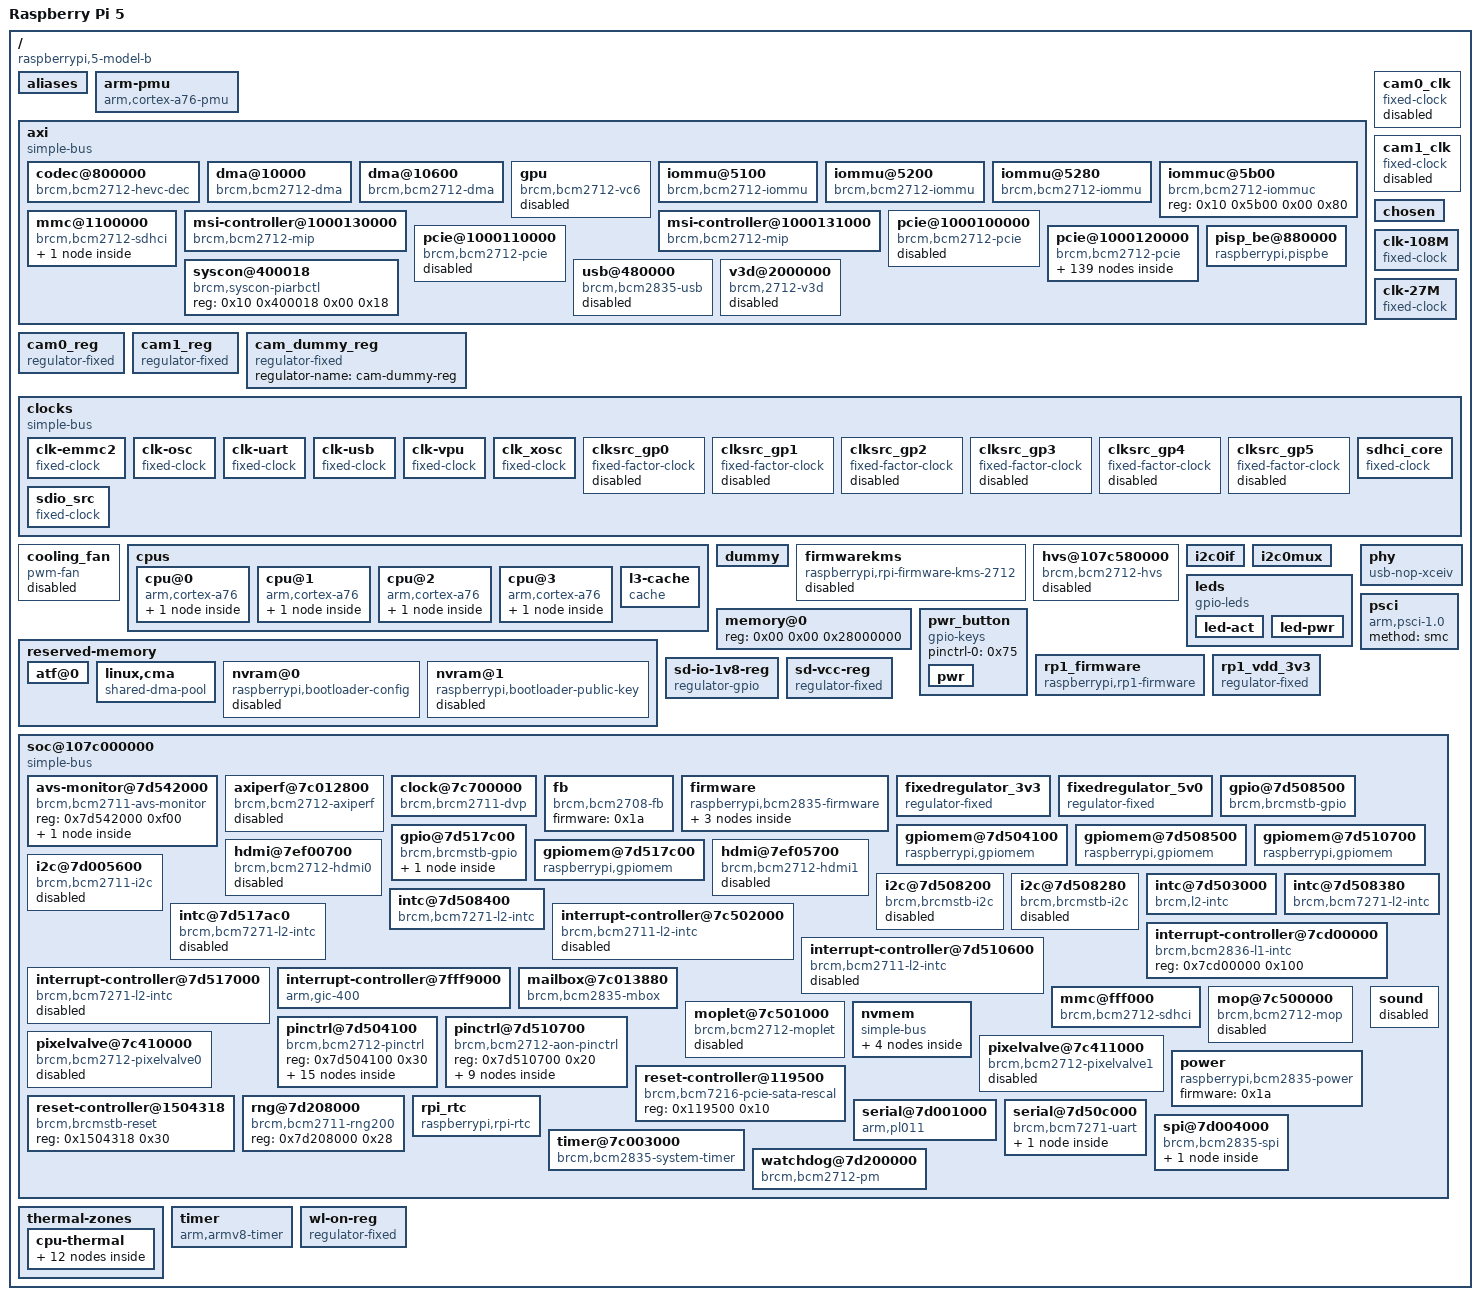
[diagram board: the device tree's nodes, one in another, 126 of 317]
/dts-v1/;

/ {
	#address-cells = <0x02>;
	#size-cells = <0x01>;
	compatible = "raspberrypi,5-model-b", "brcm,bcm2712";
	interrupt-parent = <0x01>;
	model = "Raspberry Pi 5";

	__overrides__ {
		act_led_activelow = "", "", "", "]gpios:8";
		act_led_gpio = [00 00 00 5d 67 70 69 6f 73 3a 34 00 00 00 00 5d 67 70 69 6f 73 3a 30 3d 00 00 00 00 2e];
		act_led_trigger = "", "", "", "]linux,default-trigger";
		axiperf = "", "", "", "^status";
		bdaddr = "", "", "", "_local-bd-address[";
		button_debounce = "", "", "", "`debounce-interval:0";
		cam0_reg = "", "", "", "rstatus";
		cam0_reg_gpio = [00 00 00 72 67 70 69 6f 3a 34 00 00 00 00 72 67 70 69 6f 3a 30 3d 00 00 00 00 2e];
		cam1_reg = "", "", "", "sstatus";
		cam1_reg_gpio = [00 00 00 73 67 70 69 6f 3a 34 00 00 00 00 73 67 70 69 6f 3a 30 3d 00 00 00 00 2e];
		cooling_fan = "", "", "", "Tstatus", "", "", "", "astatus";
		drm_fb0_rp1_dpi = "", "", "", "bdrm-fb0=", "/axi/pcie@1000120000/rp1/dpi@148000";
		drm_fb0_rp1_dsi0 = "", "", "", "bdrm-fb0=", "/axi/pcie@1000120000/rp1/dsi@110000";
		drm_fb0_rp1_dsi1 = "", "", "", "bdrm-fb0=", "/axi/pcie@1000120000/rp1/dsi@128000";
		drm_fb0_vc4 = "", "", "", "bdrm-fb0=", "/axi/gpu";
		drm_fb1_rp1_dpi = "", "", "", "bdrm-fb1=", "/axi/pcie@1000120000/rp1/dpi@148000";
		drm_fb1_rp1_dsi0 = "", "", "", "bdrm-fb1=", "/axi/pcie@1000120000/rp1/dsi@110000";
		drm_fb1_rp1_dsi1 = "", "", "", "bdrm-fb1=", "/axi/pcie@1000120000/rp1/dsi@128000";
		drm_fb1_vc4 = "", "", "", "bdrm-fb1=", "/axi/gpu";
		drm_fb2_rp1_dpi = "", "", "", "bdrm-fb2=", "/axi/pcie@1000120000/rp1/dpi@148000";
		drm_fb2_rp1_dsi0 = "", "", "", "bdrm-fb2=", "/axi/pcie@1000120000/rp1/dsi@110000";
		drm_fb2_rp1_dsi1 = "", "", "", "bdrm-fb2=", "/axi/pcie@1000120000/rp1/dsi@128000";
		drm_fb2_vc4 = "", "", "", "bdrm-fb2=", "/axi/gpu";
		eth_led0 = "", "", "", "?led-modes:0";
		eth_led1 = "", "", "", "?led-modes:4";
		eth_max_speed = "", "", "", "?max-speed:0";
		fan_temp0 = "", "", "", "Stemperature:0";
		fan_temp0_hyst = "", "", "", "Shysteresis:0";
		fan_temp0_speed = "", "", "", "Tcooling-levels:4";
		fan_temp1 = "", "", "", "Utemperature:0";
		fan_temp1_hyst = "", "", "", "Uhysteresis:0";
		fan_temp1_speed = "", "", "", "Tcooling-levels:8";
		fan_temp2 = "", "", "", "Vtemperature:0";
		fan_temp2_hyst = "", "", "", "Vhysteresis:0";
		fan_temp2_speed = "", "", "", "Tcooling-levels:12";
		fan_temp3 = "", "", "", "Wtemperature:0";
		fan_temp3_hyst = "", "", "", "Whysteresis:0";
		fan_temp3_speed = "", "", "", "Tcooling-levels:16";
		i2c = "", "", "", "cstatus";
		i2c0 = "", "", "", "fstatus";
		i2c0_baudrate = "", "", "", "fclock-frequency:0";
		i2c1 = "", "", "", "cstatus";
		i2c1_baudrate = "", "", "", "cclock-frequency:0";
		i2c_arm = "", "", "", "cstatus";
		i2c_arm_baudrate = "", "", "", "cclock-frequency:0";
		i2c_baudrate = "", "", "", "cclock-frequency:0";
		i2c_csi_dsi = "", "", "", "dstatus";
		i2c_csi_dsi0 = "", "", "", "estatus";
		i2c_csi_dsi1 = "", "", "", "dstatus";
		i2c_vc = "", "", "", "fstatus";
		i2c_vc_baudrate = "", "", "", "fclock-frequency:0";
		krnbt = "", "", "", "_status";
		nvme = "", "", "", "gstatus";
		nvmem_cust_rw = "", "", "", "hrw?";
		nvmem_mac_rw = "", "", "", "irw?";
		nvmem_priv_rw = "", "", "", "jrw?";
		pcie_tperst_clk_ms = "", "", "", "gbrcm,tperst-clk-ms:0";
		pciex1 = "", "", "", "gstatus";
		pciex1_gen = "", "", "", "gmax-link-speed:0";
		pciex1_no_l0s = "", "", "", "gaspm-no-l0s?";
		pciex1_tperst_clk_ms = "", "", "", "gbrcm,tperst-clk-ms:0";
		pwr_led_activelow = "", "", "", "kgpios:8";
		pwr_led_gpio = "", "", "", "kgpios:4";
		pwr_led_trigger = "", "", "", "klinux,default-trigger";
		random = "", "", "", "lstatus";
		rtc = "", "", "", "mstatus";
		rtc_bbat_vchg = "", "", "", "mtrickle-charge-microvolt:0";
		sd_cqe = "", "", "", "tsupports-cqe:0";
		spi = "", "", "", "nstatus";
		strict_gpiod = "", "", "", "obootargs=pinctrl_rp1.persist_gpio_outputs=n";
		suspend = "", "", "", "`linux,code:0=205";
		uart0 = "", "", "", "pstatus";
		uart0_console = "", "", "", "pstatus", "", "", "", "bconsole=", "/axi/pcie@1000120000/rp1/serial@30000";
		uart0_dma = [00 00 00 70 64 6d 61 73 3a 30 3d 00 00 00 00 2b 00 00 00 70 64 6d 61 73 3a 34 3d 00 00 00 00 1a 00 00 00 70 64 6d 61 73 3a 38 3d 00 00 00 00 2b 00 00 00 70 64 6d 61 73 3a 31 32 3d 00 00 00 00 19 00 00 00 70 64 6d 61 2d 6e 61 6d 65 73 5b 3d 37 34 37 38 30 30 37 32 37 38 30 30 00];
		watchdog = "", "", "", "Learly-watchdog?";
		wifiaddr = "", "", "", "qlocal-mac-address[";
	};

	__symbols__ {
		aliases = "/aliases";
		aon_intr = "/soc@107c000000/interrupt-controller@7d510600";
		aon_pwm_1pin = "/soc@107c000000/pinctrl@7d510700/aon_pwm_1pin";
		aux = "/dummy";
		avs_monitor = "/soc@107c000000/avs-monitor@7d542000";
		axi = "/axi";
		axiperf = "/soc@107c000000/axiperf@7c012800";
		bcm_reset = "/soc@107c000000/reset-controller@1504318";
		blconfig = "/reserved-memory/nvram@0";
		blpubkey = "/reserved-memory/nvram@1";
		bluetooth = "/soc@107c000000/serial@7d50c000/bluetooth";
		bsc_irq = "/soc@107c000000/intc@7d508380";
		bsc_m1_agpio13_pins = "/soc@107c000000/pinctrl@7d510700/bsc_m1_agpio13_pins";
		bsc_m2_sgpio4_pins = "/soc@107c000000/pinctrl@7d510700/bsc_m2_sgpio4_pins";
		bsc_pmu_sgpio4_pins = "/soc@107c000000/pinctrl@7d510700/bsc_pmu_sgpio4_pins";
		bt_shutdown_pins = "/soc@107c000000/pinctrl@7d504100/bt_shutdown_pins";
		cam0_clk = "/cam0_clk";
		cam0_reg = "/cam0_reg";
		cam1_clk = "/cam1_clk";
		cam1_reg = "/cam1_reg";
		cam_dummy_reg = "/cam_dummy_reg";
		chosen = "/chosen";
		clk_108MHz = "/clk-108M";
		clk_27MHz = "/clk-27M";
		clk_emmc2 = "/clocks/clk-emmc2";
		clk_osc = "/clocks/clk-osc";
		clk_uart = "/clocks/clk-uart";
		clk_usb = "/clocks/clk-usb";
		clk_vpu = "/clocks/clk-vpu";
		clk_xosc = "/clocks/clk_xosc";
		clksrc_gp0 = "/clocks/clksrc_gp0";
		clksrc_gp1 = "/clocks/clksrc_gp1";
		clksrc_gp2 = "/clocks/clksrc_gp2";
		clksrc_gp3 = "/clocks/clksrc_gp3";
		clksrc_gp4 = "/clocks/clksrc_gp4";
		clksrc_gp5 = "/clocks/clksrc_gp5";
		clocks = "/clocks";
		cma = "/reserved-memory/linux,cma";
		cooling_maps = "/thermal-zones/cpu-thermal/cooling-maps";
		cpu0 = "/cpus/cpu@0";
		cpu1 = "/cpus/cpu@1";
		cpu2 = "/cpus/cpu@2";
		cpu3 = "/cpus/cpu@3";
		cpu_crit = "/thermal-zones/cpu-thermal/trips/cpu-crit";
		cpu_hot = "/thermal-zones/cpu-thermal/trips/cpu-hot";
		cpu_l2_irq = "/soc@107c000000/intc@7d503000";
		cpu_tepid = "/thermal-zones/cpu-thermal/trips/cpu-tepid";
		cpu_thermal = "/thermal-zones/cpu-thermal";
		cpu_vhot = "/thermal-zones/cpu-thermal/trips/cpu-vhot";
		cpu_warm = "/thermal-zones/cpu-thermal/trips/cpu-warm";
		cpus = "/cpus";
		csi0 = "/axi/pcie@1000120000/rp1/csi@110000";
		csi1 = "/axi/pcie@1000120000/rp1/csi@128000";
		ddc0 = "/soc@107c000000/i2c@7d508200";
		ddc1 = "/soc@107c000000/i2c@7d508280";
		disp_intr = "/soc@107c000000/interrupt-controller@7c502000";
		dma32 = "/axi/dma@10000";
		dma40 = "/axi/dma@10600";
		dpi = "/axi/pcie@1000120000/rp1/dpi@148000";
		dpi_16bit_cpadhi_gpio0 = "/axi/pcie@1000120000/rp1/gpio@d0000/rp1_dpi_16bit_cpadhi_gpio0";
		dpi_16bit_cpadhi_gpio2 = "/axi/pcie@1000120000/rp1/gpio@d0000/rp1_dpi_16bit_cpadhi_gpio2";
		dpi_16bit_gpio0 = "/axi/pcie@1000120000/rp1/gpio@d0000/rp1_dpi_16bit_gpio0";
		dpi_16bit_gpio2 = "/axi/pcie@1000120000/rp1/gpio@d0000/rp1_dpi_16bit_gpio2";
		dpi_18bit_cpadhi_gpio0 = "/axi/pcie@1000120000/rp1/gpio@d0000/rp1_dpi_18bit_cpadhi_gpio0";
		dpi_18bit_cpadhi_gpio2 = "/axi/pcie@1000120000/rp1/gpio@d0000/rp1_dpi_18bit_cpadhi_gpio2";
		dpi_18bit_gpio0 = "/axi/pcie@1000120000/rp1/gpio@d0000/rp1_dpi_18bit_gpio0";
		dpi_18bit_gpio2 = "/axi/pcie@1000120000/rp1/gpio@d0000/rp1_dpi_18bit_gpio2";
		dpi_gpio0 = "/axi/pcie@1000120000/rp1/gpio@d0000/rp1_dpi_24bit_gpio0";
		dpi_gpio1 = "/axi/pcie@1000120000/rp1/gpio@d0000/rp1_dpi_24bit_gpio2";
		dsi0 = "/axi/pcie@1000120000/rp1/dsi@110000";
		dsi1 = "/axi/pcie@1000120000/rp1/dsi@128000";
		dummy = "/dummy";
		dvp = "/soc@107c000000/clock@7c700000";
		emmc_aon_cd_pins = "/soc@107c000000/pinctrl@7d510700/emmc_aon_cd_pins";
		emmc_sd_pulls = "/soc@107c000000/pinctrl@7d504100/emmc_sd_pulls";
		fan = "/cooling_fan";
		fb = "/soc@107c000000/fb";
		firmware = "/soc@107c000000/firmware";
		firmware_clocks = "/soc@107c000000/firmware/clocks";
		firmwarekms = "/firmwarekms";
		gicv2 = "/soc@107c000000/interrupt-controller@7fff9000";
		gio = "/soc@107c000000/gpio@7d508500";
		gio_aon = "/soc@107c000000/gpio@7d517c00";
		gpio = "/axi/pcie@1000120000/rp1/gpio@d0000";
		hdmi0 = "/soc@107c000000/hdmi@7ef00700";
		hdmi1 = "/soc@107c000000/hdmi@7ef05700";
		hevc_dec = "/axi/codec@800000";
		hvs = "/hvs@107c580000";
		i2c0 = "/axi/pcie@1000120000/rp1/i2c@70000";
		i2c0_pins = "/axi/pcie@1000120000/rp1/gpio@d0000/rp1_i2c0_0_1";
		i2c0if = "/i2c0if";
		i2c0mux = "/i2c0mux";
		i2c1 = "/axi/pcie@1000120000/rp1/i2c@74000";
		i2c10 = "/soc@107c000000/i2c@7d005600";
		i2c1_pins = "/axi/pcie@1000120000/rp1/gpio@d0000/rp1_i2c1_2_3";
		i2c2 = "/axi/pcie@1000120000/rp1/i2c@78000";
		i2c2_pins = "/axi/pcie@1000120000/rp1/gpio@d0000/rp1_i2c2_4_5";
		i2c3 = "/axi/pcie@1000120000/rp1/i2c@7c000";
		i2c3_m4_agpio0_pins = "/soc@107c000000/pinctrl@7d510700/i2c3_m4_agpio0_pins";
		i2c3_pins = "/axi/pcie@1000120000/rp1/gpio@d0000/rp1_i2c3_6_7";
		i2c4 = "/axi/pcie@1000120000/rp1/i2c@80000";
		i2c5 = "/axi/pcie@1000120000/rp1/i2c@84000";
		i2c6 = "/axi/pcie@1000120000/rp1/i2c@88000";
		i2c_arm = "/axi/pcie@1000120000/rp1/i2c@74000";
		i2c_csi_dsi = "/axi/pcie@1000120000/rp1/i2c@80000";
		i2c_csi_dsi0 = "/axi/pcie@1000120000/rp1/i2c@88000";
		i2c_csi_dsi1 = "/axi/pcie@1000120000/rp1/i2c@80000";
		i2c_vc = "/axi/pcie@1000120000/rp1/i2c@70000";
		i2s = "/axi/pcie@1000120000/rp1/i2s@a0000";
		i2s_clk_consumer = "/axi/pcie@1000120000/rp1/i2s@a4000";
		i2s_clk_producer = "/axi/pcie@1000120000/rp1/i2s@a0000";
		iommu2 = "/axi/iommu@5100";
		iommu4 = "/axi/iommu@5200";
		iommu5 = "/axi/iommu@5280";
		iommuc = "/axi/iommuc@5b00";
		l2_cache_l0 = "/cpus/cpu@0/l2-cache-l0";
		l2_cache_l1 = "/cpus/cpu@1/l2-cache-l1";
		l2_cache_l2 = "/cpus/cpu@2/l2-cache-l2";
		l2_cache_l3 = "/cpus/cpu@3/l2-cache-l3";
		l3_cache = "/cpus/l3-cache";
		led_act = "/leds/led-act";
		led_pwr = "/leds/led-pwr";
		leds = "/leds";
		local_intc = "/soc@107c000000/interrupt-controller@7cd00000";
		mailbox = "/soc@107c000000/mailbox@7c013880";
		main_aon_irq = "/soc@107c000000/intc@7d517ac0";
		main_irq = "/soc@107c000000/intc@7d508400";
		mip0 = "/axi/msi-controller@1000130000";
		mip1 = "/axi/msi-controller@1000131000";
		mop = "/soc@107c000000/mop@7c500000";
		moplet = "/soc@107c000000/moplet@7c501000";
		nvmem_cust = "/soc@107c000000/nvmem/nvmem_cust";
		nvmem_mac = "/soc@107c000000/nvmem/nvmem_mac";
		nvmem_otp = "/soc@107c000000/nvmem/nvmem_otp";
		nvmem_priv = "/soc@107c000000/nvmem/nvmem_priv";
		pcie0 = "/axi/pcie@1000100000";
		pcie1 = "/axi/pcie@1000110000";
		pcie2 = "/axi/pcie@1000120000";
		pcie_rescal = "/soc@107c000000/reset-controller@119500";
		pciex1 = "/axi/pcie@1000110000";
		pciex4 = "/axi/pcie@1000120000";
		phy1 = "/axi/pcie@1000120000/rp1/ethernet@100000/ethernet-phy@1";
		pinctrl = "/soc@107c000000/pinctrl@7d504100";
		pinctrl_aon = "/soc@107c000000/pinctrl@7d510700";
		pio = "/axi/pcie@1000120000/rp1/pio@178000";
		pisp_be = "/axi/pisp_be@880000";
		pixelvalve0 = "/soc@107c000000/pixelvalve@7c410000";
		pixelvalve1 = "/soc@107c000000/pixelvalve@7c411000";
		pm = "/soc@107c000000/watchdog@7d200000";
		power = "/soc@107c000000/power";
		pwm = "/axi/pcie@1000120000/rp1/pwm@98000";
		pwm0 = "/axi/pcie@1000120000/rp1/pwm@98000";
		pwm1 = "/axi/pcie@1000120000/rp1/pwm@9c000";
		pwm_aon_agpio1_pins = "/soc@107c000000/pinctrl@7d510700/pwm_aon_agpio1_pins";
		pwm_aon_agpio4_pins = "/soc@107c000000/pinctrl@7d510700/pwm_aon_agpio4_pins";
		pwm_aon_agpio7_pins = "/soc@107c000000/pinctrl@7d510700/pwm_aon_agpio7_pins";
		pwr_button_pins = "/soc@107c000000/pinctrl@7d504100/pwr_button_pins";
		pwr_key = "/pwr_button/pwr";
		random = "/soc@107c000000/rng@7d208000";
		reset = "/soc@107c000000/firmware/reset";
		rmem = "/reserved-memory";
		rp1 = "/axi/pcie@1000120000/rp1";
		rp1_adc = "/axi/pcie@1000120000/rp1/adc@c8000";
		rp1_audio_out = "/axi/pcie@1000120000/rp1/audio_out@94000";
		rp1_audio_out_12_13 = "/axi/pcie@1000120000/rp1/gpio@d0000/rp1_audio_out_12_13";
		rp1_clocks = "/axi/pcie@1000120000/rp1/clocks@18000";
		rp1_csi0 = "/axi/pcie@1000120000/rp1/csi@110000";
		rp1_csi1 = "/axi/pcie@1000120000/rp1/csi@128000";
		rp1_dma = "/axi/pcie@1000120000/rp1/dma@188000";
		rp1_dpi = "/axi/pcie@1000120000/rp1/dpi@148000";
		rp1_dpi_16bit_cpadhi_gpio0 = "/axi/pcie@1000120000/rp1/gpio@d0000/rp1_dpi_16bit_cpadhi_gpio0";
		rp1_dpi_16bit_cpadhi_gpio2 = "/axi/pcie@1000120000/rp1/gpio@d0000/rp1_dpi_16bit_cpadhi_gpio2";
		rp1_dpi_16bit_gpio0 = "/axi/pcie@1000120000/rp1/gpio@d0000/rp1_dpi_16bit_gpio0";
		rp1_dpi_16bit_gpio2 = "/axi/pcie@1000120000/rp1/gpio@d0000/rp1_dpi_16bit_gpio2";
		rp1_dpi_16bit_pad666_gpio0 = "/axi/pcie@1000120000/rp1/gpio@d0000/rp1_dpi_16bit_pad666_gpio0";
		rp1_dpi_16bit_pad666_gpio2 = "/axi/pcie@1000120000/rp1/gpio@d0000/rp1_dpi_16bit_pad666_gpio2";
		rp1_dpi_18bit_cpadhi_gpio0 = "/axi/pcie@1000120000/rp1/gpio@d0000/rp1_dpi_18bit_cpadhi_gpio0";
		rp1_dpi_18bit_cpadhi_gpio2 = "/axi/pcie@1000120000/rp1/gpio@d0000/rp1_dpi_18bit_cpadhi_gpio2";
		rp1_dpi_18bit_gpio0 = "/axi/pcie@1000120000/rp1/gpio@d0000/rp1_dpi_18bit_gpio0";
		rp1_dpi_18bit_gpio2 = "/axi/pcie@1000120000/rp1/gpio@d0000/rp1_dpi_18bit_gpio2";
		rp1_dpi_24bit_gpio0 = "/axi/pcie@1000120000/rp1/gpio@d0000/rp1_dpi_24bit_gpio0";
		rp1_dpi_24bit_gpio2 = "/axi/pcie@1000120000/rp1/gpio@d0000/rp1_dpi_24bit_gpio2";
		rp1_dpi_hvsync = "/axi/pcie@1000120000/rp1/gpio@d0000/rp1_dpi_hvsync";
		rp1_dsi0 = "/axi/pcie@1000120000/rp1/dsi@110000";
		rp1_dsi1 = "/axi/pcie@1000120000/rp1/dsi@128000";
		rp1_eth = "/axi/pcie@1000120000/rp1/ethernet@100000";
		rp1_firmware = "/rp1_firmware";
		rp1_fw_shmem = "/axi/pcie@1000120000/rp1/sram@400000/shmem@ff00";
		rp1_gpclksrc0_gpio20 = "/axi/pcie@1000120000/rp1/gpio@d0000/rp1_gpclksrc0_gpio20";
		rp1_gpclksrc0_gpio4 = "/axi/pcie@1000120000/rp1/gpio@d0000/rp1_gpclksrc0_gpio4";
		rp1_gpclksrc1_gpio18 = "/axi/pcie@1000120000/rp1/gpio@d0000/rp1_gpclksrc1_gpio18";
		rp1_gpclksrc1_gpio21 = "/axi/pcie@1000120000/rp1/gpio@d0000/rp1_gpclksrc1_gpio21";
		rp1_gpclksrc1_gpio5 = "/axi/pcie@1000120000/rp1/gpio@d0000/rp1_gpclksrc1_gpio5";
		rp1_gpio = "/axi/pcie@1000120000/rp1/gpio@d0000";
		rp1_i2c0 = "/axi/pcie@1000120000/rp1/i2c@70000";
		rp1_i2c0_0_1 = "/axi/pcie@1000120000/rp1/gpio@d0000/rp1_i2c0_0_1";
		rp1_i2c0_8_9 = "/axi/pcie@1000120000/rp1/gpio@d0000/rp1_i2c0_8_9";
		rp1_i2c1 = "/axi/pcie@1000120000/rp1/i2c@74000";
		rp1_i2c1_10_11 = "/axi/pcie@1000120000/rp1/gpio@d0000/rp1_i2c1_10_11";
		rp1_i2c1_2_3 = "/axi/pcie@1000120000/rp1/gpio@d0000/rp1_i2c1_2_3";
		rp1_i2c2 = "/axi/pcie@1000120000/rp1/i2c@78000";
		rp1_i2c2_12_13 = "/axi/pcie@1000120000/rp1/gpio@d0000/rp1_i2c2_12_13";
		rp1_i2c2_4_5 = "/axi/pcie@1000120000/rp1/gpio@d0000/rp1_i2c2_4_5";
		rp1_i2c3 = "/axi/pcie@1000120000/rp1/i2c@7c000";
		rp1_i2c3_14_15 = "/axi/pcie@1000120000/rp1/gpio@d0000/rp1_i2c3_14_15";
		rp1_i2c3_22_23 = "/axi/pcie@1000120000/rp1/gpio@d0000/rp1_i2c3_22_23";
		rp1_i2c3_6_7 = "/axi/pcie@1000120000/rp1/gpio@d0000/rp1_i2c3_6_7";
		rp1_i2c4 = "/axi/pcie@1000120000/rp1/i2c@80000";
		rp1_i2c4_34_35 = "/axi/pcie@1000120000/rp1/gpio@d0000/rp1_i2c4_34_35";
		rp1_i2c4_40_41 = "/axi/pcie@1000120000/rp1/gpio@d0000/rp1_i2c4_40_41";
		rp1_i2c5 = "/axi/pcie@1000120000/rp1/i2c@84000";
		rp1_i2c5_44_45 = "/axi/pcie@1000120000/rp1/gpio@d0000/rp1_i2c5_44_45";
		rp1_i2c6 = "/axi/pcie@1000120000/rp1/i2c@88000";
		rp1_i2c6_38_39 = "/axi/pcie@1000120000/rp1/gpio@d0000/rp1_i2c6_38_39";
		rp1_i2s0 = "/axi/pcie@1000120000/rp1/i2s@a0000";
		rp1_i2s0_18_21 = "/axi/pcie@1000120000/rp1/gpio@d0000/rp1_i2s0_18_21";
		rp1_i2s1 = "/axi/pcie@1000120000/rp1/i2s@a4000";
		rp1_i2s1_18_21 = "/axi/pcie@1000120000/rp1/gpio@d0000/rp1_i2s1_18_21";
		rp1_i2s2 = "/axi/pcie@1000120000/rp1/i2s@a8000";
		rp1_mbox = "/axi/pcie@1000120000/rp1/mailbox@8000";
		rp1_mmc0 = "/axi/pcie@1000120000/rp1/mmc@180000";
		rp1_mmc1 = "/axi/pcie@1000120000/rp1/mmc@184000";
		rp1_pio = "/axi/pcie@1000120000/rp1/pio@178000";
		rp1_pwm0 = "/axi/pcie@1000120000/rp1/pwm@98000";
		rp1_pwm1 = "/axi/pcie@1000120000/rp1/pwm@9c000";
		rp1_pwm1_gpio45 = "/axi/pcie@1000120000/rp1/gpio@d0000/rp1_pwm1_gpio45";
		rp1_sdio0_22_27 = "/axi/pcie@1000120000/rp1/gpio@d0000/rp1_sdio0_22_27";
		rp1_sdio1_28_33 = "/axi/pcie@1000120000/rp1/gpio@d0000/rp1_sdio1_28_33";
		rp1_sdio_clk0 = "/axi/pcie@1000120000/rp1/sdio_clk0@b0004";
		rp1_sdio_clk1 = "/axi/pcie@1000120000/rp1/sdio_clk1@b4004";
		rp1_spi0 = "/axi/pcie@1000120000/rp1/spi@50000";
		rp1_spi0_cs_gpio7 = "/axi/pcie@1000120000/rp1/gpio@d0000/rp1_spi0_cs_gpio7";
		rp1_spi0_gpio9 = "/axi/pcie@1000120000/rp1/gpio@d0000/rp1_spi0_gpio9";
		rp1_spi1 = "/axi/pcie@1000120000/rp1/spi@54000";
		rp1_spi1_gpio19 = "/axi/pcie@1000120000/rp1/gpio@d0000/rp1_spi1_gpio19";
		rp1_spi2 = "/axi/pcie@1000120000/rp1/spi@58000";
		rp1_spi2_gpio1 = "/axi/pcie@1000120000/rp1/gpio@d0000/rp1_spi2_gpio1";
		rp1_spi3 = "/axi/pcie@1000120000/rp1/spi@5c000";
		rp1_spi3_gpio5 = "/axi/pcie@1000120000/rp1/gpio@d0000/rp1_spi3_gpio5";
		rp1_spi4 = "/axi/pcie@1000120000/rp1/spi@60000";
		rp1_spi4_gpio9 = "/axi/pcie@1000120000/rp1/gpio@d0000/rp1_spi4_gpio9";
		rp1_spi5 = "/axi/pcie@1000120000/rp1/spi@64000";
		rp1_spi5_gpio13 = "/axi/pcie@1000120000/rp1/gpio@d0000/rp1_spi5_gpio13";
		rp1_spi6 = "/axi/pcie@1000120000/rp1/spi@68000";
		rp1_spi7 = "/axi/pcie@1000120000/rp1/spi@6c000";
		rp1_spi8 = "/axi/pcie@1000120000/rp1/spi@4c000";
		rp1_spi8_cs_gpio52 = "/axi/pcie@1000120000/rp1/gpio@d0000/rp1_spi8_cs_gpio52";
		rp1_spi8_gpio49 = "/axi/pcie@1000120000/rp1/gpio@d0000/rp1_spi8_gpio49";
		rp1_target = "/axi/pcie@1000120000";
		rp1_uart0 = "/axi/pcie@1000120000/rp1/serial@30000";
		rp1_uart0_14_15 = "/axi/pcie@1000120000/rp1/gpio@d0000/rp1_uart0_14_15";
		rp1_uart0_ctsrts_16_17 = "/axi/pcie@1000120000/rp1/gpio@d0000/rp1_uart0_ctsrts_16_17";
		rp1_uart1 = "/axi/pcie@1000120000/rp1/serial@34000";
		rp1_uart1_0_1 = "/axi/pcie@1000120000/rp1/gpio@d0000/rp1_uart1_0_1";
		rp1_uart1_ctsrts_2_3 = "/axi/pcie@1000120000/rp1/gpio@d0000/rp1_uart1_ctsrts_2_3";
		rp1_uart2 = "/axi/pcie@1000120000/rp1/serial@38000";
		rp1_uart2_4_5 = "/axi/pcie@1000120000/rp1/gpio@d0000/rp1_uart2_4_5";
		rp1_uart2_ctsrts_6_7 = "/axi/pcie@1000120000/rp1/gpio@d0000/rp1_uart2_ctsrts_6_7";
		rp1_uart3 = "/axi/pcie@1000120000/rp1/serial@3c000";
		rp1_uart3_8_9 = "/axi/pcie@1000120000/rp1/gpio@d0000/rp1_uart3_8_9";
		rp1_uart3_ctsrts_10_11 = "/axi/pcie@1000120000/rp1/gpio@d0000/rp1_uart3_ctsrts_10_11";
		rp1_uart4 = "/axi/pcie@1000120000/rp1/serial@40000";
		rp1_uart4_12_13 = "/axi/pcie@1000120000/rp1/gpio@d0000/rp1_uart4_12_13";
		rp1_uart4_ctsrts_14_15 = "/axi/pcie@1000120000/rp1/gpio@d0000/rp1_uart4_ctsrts_14_15";
		rp1_uart5 = "/axi/pcie@1000120000/rp1/serial@44000";
		rp1_usb0 = "/axi/pcie@1000120000/rp1/usb@200000";
		rp1_usb1 = "/axi/pcie@1000120000/rp1/usb@300000";
		rp1_vdd_3v3 = "/rp1_vdd_3v3";
		rp1_vec = "/axi/pcie@1000120000/rp1/vec@144000";
		rpi_rtc = "/soc@107c000000/rpi_rtc";
		sd_io_1v8_reg = "/sd-io-1v8-reg";
		sd_vcc_reg = "/sd-vcc-reg";
		sdhci_core = "/clocks/sdhci_core";
		sdio1 = "/soc@107c000000/mmc@fff000";
		sdio2 = "/axi/mmc@1100000";
		sdio2_30_pins = "/soc@107c000000/pinctrl@7d504100/sdio2_30_pins";
		sdio_src = "/clocks/sdio_src";
		soc = "/soc@107c000000";
		sound = "/soc@107c000000/sound";
		spi0 = "/axi/pcie@1000120000/rp1/spi@50000";
		spi0_cs_pins = "/axi/pcie@1000120000/rp1/gpio@d0000/rp1_spi0_cs_gpio7";
		spi0_pins = "/axi/pcie@1000120000/rp1/gpio@d0000/rp1_spi0_gpio9";
		spi1 = "/axi/pcie@1000120000/rp1/spi@54000";
		spi10 = "/soc@107c000000/spi@7d004000";
		spi10_cs_gpio1 = "/soc@107c000000/pinctrl@7d504100/spi10_cs_gpio1";
		spi10_cs_pins = "/soc@107c000000/pinctrl@7d504100/spi10_cs_gpio1";
		spi10_gpio2 = "/soc@107c000000/pinctrl@7d504100/spi10_gpio2";
		spi10_pins = "/soc@107c000000/pinctrl@7d504100/spi10_gpio2";
		spi2 = "/axi/pcie@1000120000/rp1/spi@58000";
		spi2_pins = "/axi/pcie@1000120000/rp1/gpio@d0000/rp1_spi2_gpio1";
		spi3 = "/axi/pcie@1000120000/rp1/spi@5c000";
		spi3_pins = "/axi/pcie@1000120000/rp1/gpio@d0000/rp1_spi3_gpio5";
		spi4 = "/axi/pcie@1000120000/rp1/spi@60000";
		spi4_pins = "/axi/pcie@1000120000/rp1/gpio@d0000/rp1_spi4_gpio9";
		spi5 = "/axi/pcie@1000120000/rp1/spi@64000";
		spi5_pins = "/axi/pcie@1000120000/rp1/gpio@d0000/rp1_spi5_gpio13";
		spidev0 = "/axi/pcie@1000120000/rp1/spi@50000/spidev@0";
		spidev1 = "/axi/pcie@1000120000/rp1/spi@50000/spidev@1";
		spidev10 = "/soc@107c000000/spi@7d004000/spidev@0";
		sram = "/axi/pcie@1000120000/rp1/sram@400000";
		syscon_piarbctl = "/axi/syscon@400018";
		system_timer = "/soc@107c000000/timer@7c003000";
		thermal = "/soc@107c000000/avs-monitor@7d542000/thermal";
		thermal_trips = "/thermal-zones/cpu-thermal/trips";
		uart0 = "/axi/pcie@1000120000/rp1/serial@30000";
		uart0_ctsrts_pins = "/axi/pcie@1000120000/rp1/gpio@d0000/rp1_uart0_ctsrts_16_17";
		uart0_pins = "/axi/pcie@1000120000/rp1/gpio@d0000/rp1_uart0_14_15";
		uart1 = "/axi/pcie@1000120000/rp1/serial@34000";
		uart10 = "/soc@107c000000/serial@7d001000";
		uart1_ctsrts_pins = "/axi/pcie@1000120000/rp1/gpio@d0000/rp1_uart1_ctsrts_2_3";
		uart1_pins = "/axi/pcie@1000120000/rp1/gpio@d0000/rp1_uart1_0_1";
		uart2 = "/axi/pcie@1000120000/rp1/serial@38000";
		uart2_ctsrts_pins = "/axi/pcie@1000120000/rp1/gpio@d0000/rp1_uart2_ctsrts_6_7";
		uart2_pins = "/axi/pcie@1000120000/rp1/gpio@d0000/rp1_uart2_4_5";
		uart3 = "/axi/pcie@1000120000/rp1/serial@3c000";
		uart3_ctsrts_pins = "/axi/pcie@1000120000/rp1/gpio@d0000/rp1_uart3_ctsrts_10_11";
		uart3_pins = "/axi/pcie@1000120000/rp1/gpio@d0000/rp1_uart3_8_9";
		uart4 = "/axi/pcie@1000120000/rp1/serial@40000";
		uart4_ctsrts_pins = "/axi/pcie@1000120000/rp1/gpio@d0000/rp1_uart4_ctsrts_14_15";
		uart4_pins = "/axi/pcie@1000120000/rp1/gpio@d0000/rp1_uart4_12_13";
		uarta = "/soc@107c000000/serial@7d50c000";
		uarta_24_pins = "/soc@107c000000/pinctrl@7d504100/uarta_24_pins";
		usb = "/axi/usb@480000";
		usb_vbus_pins = "/axi/pcie@1000120000/rp1/gpio@d0000/usb_vbus_pins";
		usbphy = "/phy";
		v3d = "/axi/v3d@2000000";
		vc4 = "/axi/gpu";
		vcio = "/soc@107c000000/firmware/vcio";
		vdd_3v3_reg = "/soc@107c000000/fixedregulator_3v3";
		vdd_5v0_reg = "/soc@107c000000/fixedregulator_5v0";
		vec = "/axi/pcie@1000120000/rp1/vec@144000";
		watchdog = "/soc@107c000000/watchdog@7d200000";
		wifi = "/axi/mmc@1100000/wifi@1";
		wl_on_pins = "/soc@107c000000/pinctrl@7d504100/wl_on_pins";
		wl_on_reg = "/wl-on-reg";
	};

	aliases {
		blconfig = "/reserved-memory/nvram@0";
		blpubkey = "/reserved-memory/nvram@1";
		bluetooth = "/soc@107c000000/serial@7d50c000/bluetooth";
		console = "/soc@107c000000/serial@7d001000";
		drm-dsi1 = "/axi/pcie@1000120000/rp1/dsi@110000";
		drm-dsi2 = "/axi/pcie@1000120000/rp1/dsi@128000";
		ethernet0 = "/axi/pcie@1000120000/rp1/ethernet@100000";
		fb = "/soc@107c000000/fb";
		gpio0 = "/axi/pcie@1000120000/rp1/gpio@d0000";
		gpio1 = "/soc@107c000000/gpio@7d508500";
		gpio2 = "/soc@107c000000/gpio@7d517c00";
		gpio3 = "/soc@107c000000/pinctrl@7d504100";
		gpio4 = "/soc@107c000000/pinctrl@7d510700";
		gpiochip0 = "/axi/pcie@1000120000/rp1/gpio@d0000";
		gpiochip10 = "/soc@107c000000/gpio@7d508500";
		i2c = "/axi/pcie@1000120000/rp1/i2c@74000";
		i2c0 = "/axi/pcie@1000120000/rp1/i2c@70000";
		i2c1 = "/axi/pcie@1000120000/rp1/i2c@74000";
		i2c10 = "/axi/pcie@1000120000/rp1/i2c@88000";
		i2c11 = "/axi/pcie@1000120000/rp1/i2c@80000";
		i2c12 = "/soc@107c000000/i2c@7d005600";
		i2c2 = "/axi/pcie@1000120000/rp1/i2c@78000";
		i2c3 = "/axi/pcie@1000120000/rp1/i2c@7c000";
		mailbox = "/soc@107c000000/mailbox@7c013880";
		mmc0 = "/soc@107c000000/mmc@fff000";
		phandle = <0x62>;
		pio0 = "/axi/pcie@1000120000/rp1/pio@178000";
		serial0 = "/axi/pcie@1000120000/rp1/serial@30000";
		serial1 = "/axi/pcie@1000120000/rp1/serial@34000";
		serial10 = "/soc@107c000000/serial@7d001000";
		serial2 = "/axi/pcie@1000120000/rp1/serial@38000";
		serial3 = "/axi/pcie@1000120000/rp1/serial@3c000";
		serial4 = "/axi/pcie@1000120000/rp1/serial@40000";
		spi0 = "/axi/pcie@1000120000/rp1/spi@50000";
		spi1 = "/axi/pcie@1000120000/rp1/spi@54000";
		spi10 = "/soc@107c000000/spi@7d004000";
		spi2 = "/axi/pcie@1000120000/rp1/spi@58000";
		spi3 = "/axi/pcie@1000120000/rp1/spi@5c000";
		spi4 = "/axi/pcie@1000120000/rp1/spi@60000";
		spi5 = "/axi/pcie@1000120000/rp1/spi@64000";
		uart0 = "/axi/pcie@1000120000/rp1/serial@30000";
		uart1 = "/axi/pcie@1000120000/rp1/serial@34000";
		uart10 = "/soc@107c000000/serial@7d001000";
		uart2 = "/axi/pcie@1000120000/rp1/serial@38000";
		uart3 = "/axi/pcie@1000120000/rp1/serial@3c000";
		uart4 = "/axi/pcie@1000120000/rp1/serial@40000";
		usb0 = "/axi/pcie@1000120000/rp1/usb@200000";
		usb1 = "/axi/pcie@1000120000/rp1/usb@300000";
		watchdog = "/soc@107c000000/watchdog@7d200000";
		wifi0 = "/axi/mmc@1100000/wifi@1";
	};

	arm-pmu {
		compatible = "arm,cortex-a76-pmu";
		interrupt-affinity = <0x4e 0x4f 0x50 0x51>;
		interrupts = <0x00 0x10 0x04 0x00 0x11 0x04 0x00 0x12 0x04 0x00 0x13 0x04>;
	};

	axi {
		#address-cells = <0x02>;
		#size-cells = <0x02>;
		compatible = "simple-bus";
		dma-ranges = <0x00 0x00 0x00 0x00 0x10 0x00 0x10 0x00 0x10 0x00 0x01 0x00 0x14 0x00 0x14 0x00 0x04 0x00 0x18 0x00 0x18 0x00 0x04 0x00 0x1c 0x00 0x1c 0x00 0x04 0x00>;
		phandle = <0xa3>;
		ranges = <0x00 0x00 0x00 0x00 0x10 0x00 0x10 0x00 0x10 0x00 0x01 0x00 0x14 0x00 0x14 0x00 0x04 0x00 0x18 0x00 0x18 0x00 0x04 0x00 0x1c 0x00 0x1c 0x00 0x04 0x00>;

		codec@800000 {
			clock-names = "hevc";
			clocks = <0x17 0x0b>;
			compatible = "brcm,bcm2712-hevc-dec", "raspberrypi,hevc-dec";
			interrupts = <0x00 0x62 0x04>;
			iommus = <0x49>;
			phandle = <0xf6>;
			reg = <0x10 0x800000 0x00 0x10000 0x10 0x840000 0x00 0x1000>;
			reg-names = "hevc", "intc";
		};

		dma@10000 {
			#dma-cells = <0x01>;
			brcm,dma-channel-mask = <0x3f>;
			compatible = "brcm,bcm2712-dma";
			interrupt-names = "dma0", "dma1", "dma2", "dma3", "dma4", "dma5";
			interrupts = <0x00 0x50 0x04 0x00 0x51 0x04 0x00 0x52 0x04 0x00 0x53 0x04 0x00 0x54 0x04 0x00 0x55 0x04>;
			phandle = <0xf3>;
			reg = <0x10 0x10000 0x00 0x600>;
		};

		dma@10600 {
			#dma-cells = <0x01>;
			brcm,dma-channel-mask = <0x7c0>;
			compatible = "brcm,bcm2712-dma";
			interrupt-names = "dma6", "dma7", "dma8", "dma9", "dma10", "dma11";
			interrupts = <0x00 0x56 0x04 0x00 0x57 0x04 0x00 0x58 0x04 0x00 0x59 0x04 0x00 0x5a 0x04 0x00 0x5b 0x04>;
			phandle = <0x16>;
			reg = <0x10 0x10600 0x00 0x600>;
		};

		gpu {
			compatible = "brcm,bcm2712-vc6";
			phandle = <0xa4>;
			status = "disabled";
		};

		iommu@5100 {
			#iommu-cells = <0x00>;
			cache = <0x45>;
			compatible = "brcm,bcm2712-iommu";
			phandle = <0x49>;
			reg = <0x10 0x5100 0x00 0x80>;
		};

		iommu@5200 {
			#interconnect-cells = <0x00>;
			#iommu-cells = <0x00>;
			cache = <0x45>;
			compatible = "brcm,bcm2712-iommu";
			phandle = <0x4d>;
			reg = <0x10 0x5200 0x00 0x80>;
		};

		iommu@5280 {
			#iommu-cells = <0x00>;
			cache = <0x45>;
			compatible = "brcm,bcm2712-iommu";
			dma-iova-offset = <0x10 0x00>;
			phandle = <0x40>;
			reg = <0x10 0x5280 0x00 0x80>;
		};

		iommuc@5b00 {
			compatible = "brcm,bcm2712-iommuc";
			phandle = <0x45>;
			reg = <0x10 0x5b00 0x00 0x80>;
		};

		mmc@1100000 {
			#address-cells = <0x01>;
			#size-cells = <0x00>;
			bus-width = <0x04>;
			clocks = <0x08>;
			compatible = "brcm,bcm2712-sdhci";
			interrupts = <0x00 0x112 0x04>;
			mmc-ddr-3_3v;
			non-removable;
			phandle = <0xf8>;
			pinctrl-0 = <0x4a>;
			pinctrl-names = "default";
			reg = <0x10 0x1100000 0x00 0x260 0x10 0x1100400 0x00 0x200>;
			reg-names = "host", "cfg";
			sd-uhs-ddr50;
			sdhci-caps = <0x00 0x00>;
			sdhci-caps-mask = <0xc000 0x00>;
			status = "okay";
			supports-cqe = <0x01>;
			vmmc-supply = <0x4b>;

			wifi@1 {
				compatible = "brcm,bcm4329-fmac";
				local-mac-address = [00 00 00 00 00 00];
				phandle = <0x71>;
				reg = <0x01>;
			};
		};

		msi-controller@1000130000 {
			brcm,msi-offset = <0x00>;
			compatible = "brcm,bcm2712-mip";
			msi-controller;
			msi-ranges = <0x01 0x00 0x80 0x01 0x40>;
			phandle = <0x27>;
			reg = <0x10 0x130000 0x00 0xc0 0xff 0xfffff000 0x00 0x1000>;
		};

		msi-controller@1000131000 {
			brcm,msi-offset = <0x08>;
			compatible = "brcm,bcm2712-mip";
			msi-controller;
			msi-ranges = <0x01 0x00 0xf7 0x01 0x08>;
			phandle = <0x26>;
			reg = <0x10 0x131000 0x00 0xc0 0xff 0xfffff000 0x00 0x1000>;
		};

		pcie@1000100000 {
			#address-cells = <0x03>;
			#interrupt-cells = <0x01>;
			#size-cells = <0x02>;
			compatible = "brcm,bcm2712-pcie";
			device_type = "pci";
			dma-ranges = <0x43000000 0x10 0x00 0x00 0x00 0x10 0x00>;
			interrupt-map = <0x00 0x00 0x00 0x01 0x01 0x00 0xd1 0x04 0x00 0x00 0x00 0x02 0x01 0x00 0xd2 0x04 0x00 0x00 0x00 0x03 0x01 0x00 0xd3 0x04 0x00 0x00 0x00 0x04 0x01 0x00 0xd4 0x04>;
			interrupt-map-mask = <0x00 0x00 0x00 0x07>;
			interrupt-names = "pcie", "msi";
			interrupt-parent = <0x01>;
			interrupts = <0x00 0xd5 0x04 0x00 0xd6 0x04>;
			linux,pci-domain = <0x00>;
			max-link-speed = <0x02>;
			msi-controller;
			msi-parent = <0x25>;
			num-lanes = <0x01>;
			phandle = <0x25>;
			ranges = <0x2000000 0x00 0x00 0x17 0x00 0x00 0xfffffffc 0x43000000 0x04 0x00 0x14 0x00 0x03 0x00>;
			reg = <0x10 0x100000 0x00 0x9310>;
			reset-names = "rescal", "bridge";
			resets = <0x23 0x24 0x2a>;
			status = "disabled";
		};

		pcie@1000110000 {
			#address-cells = <0x03>;
			#interrupt-cells = <0x01>;
			#size-cells = <0x02>;
			brcm,clkreq-mode = "safe";
			brcm,fifo-qos-map = <0x3030303>;
			compatible = "brcm,bcm2712-pcie";
			device_type = "pci";
			dma-ranges = <0x3000000 0x10 0x00 0x00 0x00 0x10 0x00 0x3000000 0xff 0xfffff000 0x10 0x131000 0x00 0x1000>;
			interrupt-map = <0x00 0x00 0x00 0x01 0x01 0x00 0xdb 0x04 0x00 0x00 0x00 0x02 0x01 0x00 0xdc 0x04 0x00 0x00 0x00 0x03 0x01 0x00 0xdd 0x04 0x00 0x00 0x00 0x04 0x01 0x00 0xde 0x04>;
			interrupt-map-mask = <0x00 0x00 0x00 0x07>;
			interrupt-names = "pcie", "msi";
			interrupt-parent = <0x01>;
			interrupts = <0x00 0xdf 0x04 0x00 0xe0 0x04>;
			linux,pci-domain = <0x01>;
			max-link-speed = <0x02>;
			msi-controller;
			msi-parent = <0x26>;
			num-lanes = <0x01>;
			phandle = <0x67>;
			ranges = <0x2000000 0x00 0x80000000 0x1b 0x80000000 0x00 0x80000000 0x43000000 0x04 0x00 0x18 0x00 0x03 0x80000000>;
			reg = <0x10 0x110000 0x00 0x9310>;
			reset-names = "rescal", "bridge";
			resets = <0x23 0x24 0x2b>;
			status = "disabled";
		};

		pcie@1000120000 {
			#address-cells = <0x03>;
			#interrupt-cells = <0x01>;
			#size-cells = <0x02>;
			aspm-no-l0s;
			brcm,vdm-qos-map = <0x8080809 0xa0a0b0b>;
			compatible = "brcm,bcm2712-pcie";
			device_type = "pci";
			dma-ranges = <0x2000000 0x00 0x00 0x1f 0x00 0x00 0x400000 0x43000000 0x10 0x00 0x00 0x00 0x10 0x00 0x3000000 0xff 0xfffff000 0x10 0x130000 0x00 0x1000>;
			interrupt-map = <0x00 0x00 0x00 0x01 0x01 0x00 0xe5 0x04 0x00 0x00 0x00 0x02 0x01 0x00 0xe6 0x04 0x00 0x00 0x00 0x03 0x01 0x00 0xe7 0x04 0x00 0x00 0x00 0x04 0x01 0x00 0xe8 0x04>;
			interrupt-map-mask = <0x00 0x00 0x00 0x07>;
			interrupt-names = "pcie", "msi";
			interrupt-parent = <0x01>;
			interrupts = <0x00 0xe9 0x04 0x00 0xea 0x04>;
			linux,pci-domain = <0x02>;
			max-link-speed = <0x02>;
			msi-controller;
			msi-parent = <0x27>;
			num-lanes = <0x04>;
			phandle = <0xa5>;
			ranges = <0x2000000 0x00 0x00 0x1f 0x00 0x00 0xfffffffc 0x43000000 0x04 0x00 0x1c 0x00 0x03 0x00>;
			reg = <0x10 0x120000 0x00 0x9310>;
			reset-names = "rescal", "bridge";
			resets = <0x23 0x24 0x2c>;
			status = "okay";

			rp1 {
				#address-cells = <0x02>;
				#interrupt-cells = <0x02>;
				#size-cells = <0x02>;
				compatible = "simple-bus";
				dma-ranges = <0x10 0x00 0x43000000 0x10 0x00 0x10 0x00 0xc0 0x40000000 0x2000000 0x00 0x00 0x00 0x410000 0x00 0x00 0x2000000 0x10 0x00 0x10 0x00>;
				interrupt-controller;
				interrupt-parent = <0x28>;
				phandle = <0x28>;
				ranges = <0xc0 0x40000000 0x2000000 0x00 0x00 0x00 0x410000>;

				adc@c8000 {
					#clock-cells = <0x00>;
					clock-names = "adcclk";
					clocks = <0x02 0x1e>;
					compatible = "raspberrypi,rp1-adc";
					phandle = <0xbd>;
					reg = <0xc0 0x400c8000 0x00 0x4000>;
					status = "okay";
					vref-supply = <0x3e>;
				};

				audio_out@94000 {
					#sound-dai-cells = <0x00>;
					assigned-clock-parents = <0x02 0x0a>;
					assigned-clock-rates = <0x927c000>;
					assigned-clocks = <0x02 0x14>;
					clocks = <0x02 0x14>;
					compatible = "raspberrypi,rp1-audio-out";
					dma-maxburst = <0x04>;
					dma-names = "tx";
					dmas = <0x2b 0x1d>;
					phandle = <0xb8>;
					reg = <0xc0 0x40094000 0x00 0x4000>;
					status = "disabled";
				};

				clocks@18000 {
					#clock-cells = <0x01>;
					assigned-clock-rates = <0x3b9aca00 0x5b8d8000 0xbebc200 0x7735940 0x7735940 0x3a98000 0x927c000 0xbebc200 0x5f5e100 0x2faf080 0xf4240 0xbebc200 0x2faf080>;
					assigned-clocks = <0x02 0x00 0x02 0x01 0x02 0x03 0x02 0x09 0x02 0x10 0x02 0x04 0x02 0x0a 0x02 0x0c 0x02 0x06 0x02 0x0d 0x02 0x1f 0x02 0x20 0x02 0x1d>;
					clocks = <0x29>;
					compatible = "raspberrypi,rp1-clocks";
					phandle = <0x02>;
					reg = <0xc0 0x40018000 0x00 0x10038>;
				};

				csi@110000 {
					#address-cells = <0x01>;
					#size-cells = <0x00>;
					assigned-clock-rates = <0x17d7840>;
					assigned-clocks = <0x02 0x16>;
					clocks = <0x02 0x16>;
					compatible = "raspberrypi,rp1-cfe";
					interrupts = <0x2f 0x04>;
					iommus = <0x40>;
					phandle = <0xe7>;
					reg = <0xc0 0x40110000 0x00 0x100 0xc0 0x40114000 0x00 0x100 0xc0 0x40120000 0x00 0x100 0xc0 0x40124000 0x00 0x1000>;
					status = "disabled";
				};

				csi@128000 {
					#address-cells = <0x01>;
					#size-cells = <0x00>;
					assigned-clock-rates = <0x17d7840>;
					assigned-clocks = <0x02 0x17>;
					clocks = <0x02 0x17>;
					compatible = "raspberrypi,rp1-cfe";
					interrupts = <0x30 0x04>;
					iommus = <0x40>;
					phandle = <0xe8>;
					reg = <0xc0 0x40128000 0x00 0x100 0xc0 0x4012c000 0x00 0x100 0xc0 0x40138000 0x00 0x100 0xc0 0x4013c000 0x00 0x1000>;
					status = "disabled";
				};

				dma@188000 {
					#dma-cells = <0x01>;
					clock-names = "core-clk", "cfgr-clk";
					clocks = <0x02 0x0e 0x02 0x0c>;
					compatible = "snps,axi-dma-1.01a";
					dma-channels = <0x08>;
					interrupts = <0x28 0x04>;
					phandle = <0x2b>;
					reg = <0xc0 0x40188000 0x00 0x1000>;
					snps,axi-max-burst-len = <0x08 0x08 0x04 0x04 0x04 0x04 0x04 0x04>;
					snps,block-size = <0x40000 0x40000 0x40000 0x40000 0x40000 0x40000 0x40000 0x40000>;
					snps,data-width = <0x04>;
					snps,dma-masters = <0x01>;
					snps,dma-targets = <0x40>;
					snps,priority = <0x00 0x01 0x02 0x03 0x04 0x05 0x06 0x07>;
					snps,sel-preclude = <0x00 0x00 0x200 0x200 0x200 0x200 0x200 0x200>;
					snps,sel-require = <0x100 0x100 0x00 0x00 0x00 0x00 0x00 0x00>;
					status = "okay";
				};

				dpi@148000 {
					assigned-clock-parents = <0x02 0x05>;
					assigned-clocks = <0x02 0x28>;
					clock-names = "dpiclk", "plldiv", "pllcore";
					clocks = <0x02 0x28 0x02 0x05 0x02 0x02>;
					compatible = "raspberrypi,rp1dpi";
					interrupts = <0x31 0x04>;
					iommus = <0x40>;
					phandle = <0xf1>;
					reg = <0xc0 0x40148000 0x00 0x1000 0xc0 0x40140000 0x00 0x1000>;
					status = "disabled";
				};

				dsi@110000 {
					assigned-clock-rates = <0x17d7840>;
					assigned-clocks = <0x02 0x16>;
					clock-names = "cfgclk", "dpiclk", "byteclk", "refclk", "pllsys";
					clocks = <0x02 0x16 0x02 0x29 0x02 0x2d 0x29 0x02 0x03>;
					compatible = "raspberrypi,rp1dsi";
					interrupts = <0x2f 0x04>;
					iommus = <0x40>;
					phandle = <0xee>;
					reg = <0xc0 0x40118000 0x00 0x1000 0xc0 0x4011c000 0x00 0x1000 0xc0 0x40120000 0x00 0x1000>;
					status = "disabled";
				};

				dsi@128000 {
					assigned-clock-rates = <0x17d7840>;
					assigned-clocks = <0x02 0x17>;
					clock-names = "cfgclk", "dpiclk", "byteclk", "refclk", "pllsys";
					clocks = <0x02 0x17 0x02 0x2a 0x02 0x2e 0x29 0x02 0x03>;
					compatible = "raspberrypi,rp1dsi";
					interrupts = <0x30 0x04>;
					iommus = <0x40>;
					phandle = <0xef>;
					reg = <0xc0 0x40130000 0x00 0x1000 0xc0 0x40134000 0x00 0x1000 0xc0 0x40138000 0x00 0x1000>;
					status = "disabled";
				};

				ethernet@100000 {
					#address-cells = <0x01>;
					#size-cells = <0x00>;
					cdns,ar2r-max-pipe = [08];
					cdns,aw2w-max-pipe = [08];
					cdns,use-aw2b-fill;
					clock-names = "pclk", "hclk", "tsu_clk", "tx_clk";
					clocks = <0x02 0x0c 0x02 0x0c 0x02 0x1d 0x02 0x10>;
					compatible = "raspberrypi,rp1-gem", "cdns,macb";
					interrupts = <0x06 0x04>;
					local-mac-address = [00 00 00 00 00 00];
					phandle = <0xe6>;
					phy-handle = <0x3f>;
					phy-mode = "rgmii-id";
					phy-reset-duration = <0x05>;
					phy-reset-gpios = <0x2e 0x20 0x01>;
					reg = <0xc0 0x40100000 0x00 0x4000>;
					status = "okay";

					ethernet-phy@1 {
						brcm,powerdown-enable;
						eee-broken-1000t;
						eee-broken-100tx;
						phandle = <0x3f>;
						reg = <0x01>;
					};
				};

				gpio@d0000 {
					#gpio-cells = <0x02>;
					#interrupt-cells = <0x02>;
					compatible = "raspberrypi,rp1-gpio";
					gpio-controller;
					gpio-line-names = "ID_SDA", "ID_SCL", "GPIO2", "GPIO3", "GPIO4", "GPIO5", "GPIO6", "GPIO7", "GPIO8", "GPIO9", "GPIO10", "GPIO11", "GPIO12", "GPIO13", "GPIO14", "GPIO15", "GPIO16", "GPIO17", "GPIO18", "GPIO19", "GPIO20", "GPIO21", "GPIO22", "GPIO23", "GPIO24", "GPIO25", "GPIO26", "GPIO27", "PCIE_RP1_WAKE", "FAN_TACH", "HOST_SDA", "HOST_SCL", "ETH_RST_N", "-", "CD0_IO0_MICCLK", "CD0_IO0_MICDAT0", "RP1_PCIE_CLKREQ_N", "-", "CD0_SDA", "CD0_SCL", "CD1_SDA", "CD1_SCL", "USB_VBUS_EN", "USB_OC_N", "RP1_STAT_LED", "FAN_PWM", "CD1_IO0_MICCLK", "2712_WAKE", "CD1_IO1_MICDAT1", "EN_MAX_USB_CUR", "-", "-", "-", "-";
					gpio-ranges = <0x2e 0x00 0x00 0x36>;
					interrupt-controller;
					interrupts = <0x00 0x04 0x01 0x04 0x02 0x04>;
					phandle = <0x2e>;
					reg = <0xc0 0x400d0000 0x00 0xc000 0xc0 0x400e0000 0x00 0xc000 0xc0 0x400f0000 0x00 0xc000>;
					status = "okay";

					rp1_audio_out_12_13 {
						bias-disable;
						function = "aaud";
						phandle = <0xe5>;
						pins = "gpio12", "gpio13";
					};

					rp1_dpi_16bit_cpadhi_gpio0 {
						bias-disable;
						function = "dpi";
						phandle = <0xd8>;
						pins = "gpio0", "gpio1", "gpio2", "gpio3", "gpio4", "gpio5", "gpio6", "gpio7", "gpio8", "gpio12", "gpio13", "gpio14", "gpio15", "gpio16", "gpio17", "gpio20", "gpio21", "gpio22", "gpio23", "gpio24";
					};

					rp1_dpi_16bit_cpadhi_gpio2 {
						bias-disable;
						function = "dpi";
						phandle = <0xd1>;
						pins = "gpio2", "gpio3", "gpio4", "gpio5", "gpio6", "gpio7", "gpio8", "gpio12", "gpio13", "gpio14", "gpio15", "gpio16", "gpio17", "gpio20", "gpio21", "gpio22", "gpio23", "gpio24";
					};

					rp1_dpi_16bit_gpio0 {
						bias-disable;
						function = "dpi";
						phandle = <0xd7>;
						pins = "gpio0", "gpio1", "gpio2", "gpio3", "gpio4", "gpio5", "gpio6", "gpio7", "gpio8", "gpio9", "gpio10", "gpio11", "gpio12", "gpio13", "gpio14", "gpio15", "gpio16", "gpio17", "gpio18", "gpio19";
					};

					rp1_dpi_16bit_gpio2 {
						bias-disable;
						function = "dpi";
						phandle = <0xd0>;
						pins = "gpio2", "gpio3", "gpio4", "gpio5", "gpio6", "gpio7", "gpio8", "gpio9", "gpio10", "gpio11", "gpio12", "gpio13", "gpio14", "gpio15", "gpio16", "gpio17", "gpio18", "gpio19";
					};

					rp1_dpi_16bit_pad666_gpio0 {
						bias-disable;
						function = "dpi";
						phandle = <0xd9>;
						pins = "gpio0", "gpio1", "gpio2", "gpio3", "gpio5", "gpio6", "gpio7", "gpio8", "gpio9", "gpio12", "gpio13", "gpio14", "gpio15", "gpio16", "gpio17", "gpio21", "gpio22", "gpio23", "gpio24", "gpio25";
					};

					rp1_dpi_16bit_pad666_gpio2 {
						bias-disable;
						function = "dpi";
						phandle = <0xd2>;
						pins = "gpio2", "gpio3", "gpio5", "gpio6", "gpio7", "gpio8", "gpio9", "gpio12", "gpio13", "gpio14", "gpio15", "gpio16", "gpio17", "gpio21", "gpio22", "gpio23", "gpio24", "gpio25";
					};

					rp1_dpi_18bit_cpadhi_gpio0 {
						bias-disable;
						function = "dpi";
						phandle = <0xdb>;
						pins = "gpio0", "gpio1", "gpio2", "gpio3", "gpio4", "gpio5", "gpio6", "gpio7", "gpio8", "gpio9", "gpio12", "gpio13", "gpio14", "gpio15", "gpio16", "gpio17", "gpio20", "gpio21", "gpio22", "gpio23", "gpio24", "gpio25";
					};

					rp1_dpi_18bit_cpadhi_gpio2 {
						bias-disable;
						function = "dpi";
						phandle = <0xd4>;
						pins = "gpio2", "gpio3", "gpio4", "gpio5", "gpio6", "gpio7", "gpio8", "gpio9", "gpio12", "gpio13", "gpio14", "gpio15", "gpio16", "gpio17", "gpio20", "gpio21", "gpio22", "gpio23", "gpio24", "gpio25";
					};

					rp1_dpi_18bit_gpio0 {
						bias-disable;
						function = "dpi";
						phandle = <0xda>;
						pins = "gpio0", "gpio1", "gpio2", "gpio3", "gpio4", "gpio5", "gpio6", "gpio7", "gpio8", "gpio9", "gpio10", "gpio11", "gpio12", "gpio13", "gpio14", "gpio15", "gpio16", "gpio17", "gpio18", "gpio19", "gpio20", "gpio21";
					};

					rp1_dpi_18bit_gpio2 {
						bias-disable;
						function = "dpi";
						phandle = <0xd3>;
						pins = "gpio2", "gpio3", "gpio4", "gpio5", "gpio6", "gpio7", "gpio8", "gpio9", "gpio10", "gpio11", "gpio12", "gpio13", "gpio14", "gpio15", "gpio16", "gpio17", "gpio18", "gpio19", "gpio20", "gpio21";
					};

					rp1_dpi_24bit_gpio0 {
						bias-disable;
						function = "dpi";
						phandle = <0xdc>;
						pins = "gpio0", "gpio1", "gpio2", "gpio3", "gpio4", "gpio5", "gpio6", "gpio7", "gpio8", "gpio9", "gpio10", "gpio11", "gpio12", "gpio13", "gpio14", "gpio15", "gpio16", "gpio17", "gpio18", "gpio19", "gpio20", "gpio21", "gpio22", "gpio23", "gpio24", "gpio25", "gpio26", "gpio27";
					};

					rp1_dpi_24bit_gpio2 {
						bias-disable;
						function = "dpi";
						phandle = <0xd5>;
						pins = "gpio2", "gpio3", "gpio4", "gpio5", "gpio6", "gpio7", "gpio8", "gpio9", "gpio10", "gpio11", "gpio12", "gpio13", "gpio14", "gpio15", "gpio16", "gpio17", "gpio18", "gpio19", "gpio20", "gpio21", "gpio22", "gpio23", "gpio24", "gpio25", "gpio26", "gpio27";
					};

					rp1_dpi_hvsync {
						bias-disable;
						function = "dpi";
						phandle = <0xd6>;
						pins = "gpio2", "gpio3";
					};

					rp1_gpclksrc0_gpio20 {
						bias-disable;
						function = "gpclk0";
						phandle = <0xde>;
						pins = "gpio20";
					};

					rp1_gpclksrc0_gpio4 {
						bias-disable;
						function = "gpclk0";
						phandle = <0xdd>;
						pins = "gpio4";
					};

					rp1_gpclksrc1_gpio18 {
						bias-disable;
						function = "gpclk1";
						phandle = <0xe0>;
						pins = "gpio18";
					};

					rp1_gpclksrc1_gpio21 {
						bias-disable;
						function = "gpclk1";
						phandle = <0xe1>;
						pins = "gpio21";
					};

					rp1_gpclksrc1_gpio5 {
						bias-disable;
						function = "gpclk1";
						phandle = <0xdf>;
						pins = "gpio5";
					};

					rp1_i2c0_0_1 {
						bias-pull-up;
						drive-strength = <0x0c>;
						function = "i2c0";
						phandle = <0x33>;
						pins = "gpio0", "gpio1";
					};

					rp1_i2c0_8_9 {
						bias-pull-up;
						drive-strength = <0x0c>;
						function = "i2c0";
						phandle = <0xcb>;
						pins = "gpio8", "gpio9";
					};

					rp1_i2c1_10_11 {
						bias-pull-up;
						drive-strength = <0x0c>;
						function = "i2c1";
						phandle = <0xcc>;
						pins = "gpio10", "gpio11";
					};

					rp1_i2c1_2_3 {
						bias-pull-up;
						drive-strength = <0x0c>;
						function = "i2c1";
						phandle = <0x34>;
						pins = "gpio2", "gpio3";
					};

					rp1_i2c2_12_13 {
						bias-pull-up;
						drive-strength = <0x0c>;
						function = "i2c2";
						phandle = <0xcd>;
						pins = "gpio12", "gpio13";
					};

					rp1_i2c2_4_5 {
						bias-pull-up;
						drive-strength = <0x0c>;
						function = "i2c2";
						phandle = <0x35>;
						pins = "gpio4", "gpio5";
					};

					rp1_i2c3_14_15 {
						bias-pull-up;
						drive-strength = <0x0c>;
						function = "i2c3";
						phandle = <0xce>;
						pins = "gpio14", "gpio15";
					};

					rp1_i2c3_22_23 {
						bias-pull-up;
						drive-strength = <0x0c>;
						function = "i2c3";
						phandle = <0xcf>;
						pins = "gpio22", "gpio23";
					};

					rp1_i2c3_6_7 {
						bias-pull-up;
						drive-strength = <0x0c>;
						function = "i2c3";
						phandle = <0x36>;
						pins = "gpio6", "gpio7";
					};

					rp1_i2c4_34_35 {
						bias-pull-up;
						drive-strength = <0x0c>;
						function = "i2c4";
						phandle = <0xc9>;
						pins = "gpio34", "gpio35";
					};

					rp1_i2c4_40_41 {
						bias-pull-up;
						drive-strength = <0x0c>;
						function = "i2c4";
						phandle = <0x37>;
						pins = "gpio40", "gpio41";
					};

					rp1_i2c5_44_45 {
						bias-pull-up;
						drive-strength = <0x0c>;
						function = "i2c5";
						phandle = <0xca>;
						pins = "gpio44", "gpio45";
					};

					rp1_i2c6_38_39 {
						bias-pull-up;
						drive-strength = <0x0c>;
						function = "i2c6";
						phandle = <0x38>;
						pins = "gpio38", "gpio39";
					};

					rp1_i2s0_18_21 {
						bias-disable;
						function = "i2s0";
						phandle = <0x3a>;
						pins = "gpio18", "gpio19", "gpio20", "gpio21";
					};

					rp1_i2s1_18_21 {
						bias-disable;
						function = "i2s1";
						phandle = <0x3b>;
						pins = "gpio18", "gpio19", "gpio20", "gpio21";
					};

					rp1_pwm1_gpio45 {
						bias-pull-down;
						function = "pwm1";
						phandle = <0x39>;
						pins = "gpio45";
					};

					rp1_sdio0_22_27 {
						phandle = <0xc7>;

						pin_clk {
							bias-disable;
							drive-strength = <0x0c>;
							function = "sd0";
							pins = "gpio22";
							slew-rate = <0x01>;
						};

						pin_cmd {
							bias-pull-up;
							drive-strength = <0x0c>;
							function = "sd0";
							pins = "gpio23";
							slew-rate = <0x01>;
						};

						pins_dat {
							bias-pull-up;
							drive-strength = <0x0c>;
							function = "sd0";
							pins = "gpio24", "gpio25", "gpio26", "gpio27";
							slew-rate = <0x01>;
						};
					};

					rp1_sdio1_28_33 {
						phandle = <0xc8>;

						pin_clk {
							bias-disable;
							drive-strength = <0x0c>;
							function = "sd1";
							pins = "gpio28";
							slew-rate = <0x01>;
						};

						pin_cmd {
							bias-pull-up;
							drive-strength = <0x0c>;
							function = "sd1";
							pins = "gpio29";
							slew-rate = <0x01>;
						};

						pins_dat {
							bias-pull-up;
							drive-strength = <0x0c>;
							function = "sd1";
							pins = "gpio30", "gpio31", "gpio32", "gpio33";
							slew-rate = <0x01>;
						};
					};

					rp1_spi0_cs_gpio7 {
						bias-pull-up;
						function = "spi0";
						phandle = <0x2d>;
						pins = "gpio7", "gpio8";
					};

					rp1_spi0_gpio9 {
						bias-disable;
						drive-strength = <0x0c>;
						function = "spi0";
						phandle = <0x2c>;
						pins = "gpio9", "gpio10", "gpio11";
						slew-rate = <0x01>;
					};

					rp1_spi1_gpio19 {
						bias-disable;
						drive-strength = <0x0c>;
						function = "spi1";
						phandle = <0xe2>;
						pins = "gpio19", "gpio20", "gpio21";
						slew-rate = <0x01>;
					};

					rp1_spi2_gpio1 {
						bias-disable;
						drive-strength = <0x0c>;
						function = "spi2";
						phandle = <0x2f>;
						pins = "gpio1", "gpio2", "gpio3";
						slew-rate = <0x01>;
					};

					rp1_spi3_gpio5 {
						bias-disable;
						drive-strength = <0x0c>;
						function = "spi3";
						phandle = <0x30>;
						pins = "gpio5", "gpio6", "gpio7";
						slew-rate = <0x01>;
					};

					rp1_spi4_gpio9 {
						bias-disable;
						drive-strength = <0x0c>;
						function = "spi4";
						phandle = <0x31>;
						pins = "gpio9", "gpio10", "gpio11";
						slew-rate = <0x01>;
					};

					rp1_spi5_gpio13 {
						bias-disable;
						drive-strength = <0x0c>;
						function = "spi5";
						phandle = <0x32>;
						pins = "gpio13", "gpio14", "gpio15";
						slew-rate = <0x01>;
					};

					rp1_spi8_cs_gpio52 {
						bias-pull-up;
						function = "spi0";
						phandle = <0xe4>;
						pins = "gpio52", "gpio53";
					};

					rp1_spi8_gpio49 {
						bias-disable;
						drive-strength = <0x0c>;
						function = "spi8";
						phandle = <0xe3>;
						pins = "gpio49", "gpio50", "gpio51";
						slew-rate = <0x01>;
					};

					rp1_uart0_14_15 {
						phandle = <0x2a>;

						pin_rxd {
							bias-pull-up;
							function = "uart0";
							pins = "gpio15";
						};

						pin_txd {
							bias-disable;
							function = "uart0";
							pins = "gpio14";
						};
					};

					rp1_uart0_ctsrts_16_17 {
						phandle = <0xbe>;

						pin_cts {
							bias-pull-up;
							function = "uart0";
							pins = "gpio16";
						};

						pin_rts {
							bias-disable;
							function = "uart0";
							pins = "gpio17";
						};
					};

					rp1_uart1_0_1 {
						phandle = <0xbf>;

						pin_rxd {
							bias-pull-up;
							function = "uart1";
							pins = "gpio1";
						};

						pin_txd {
							bias-disable;
							function = "uart1";
							pins = "gpio0";
						};
					};

					rp1_uart1_ctsrts_2_3 {
						phandle = <0xc0>;

						pin_cts {
							bias-pull-up;
							function = "uart1";
							pins = "gpio2";
						};

						pin_rts {
							bias-disable;
							function = "uart1";
							pins = "gpio3";
						};
					};

					rp1_uart2_4_5 {
						phandle = <0xc1>;

						pin_rxd {
							bias-pull-up;
							function = "uart2";
							pins = "gpio5";
						};

						pin_txd {
							bias-disable;
							function = "uart2";
							pins = "gpio4";
						};
					};

					rp1_uart2_ctsrts_6_7 {
						phandle = <0xc2>;

						pin_cts {
							bias-pull-up;
							function = "uart2";
							pins = "gpio6";
						};

						pin_rts {
							bias-disable;
							function = "uart2";
							pins = "gpio7";
						};
					};

					rp1_uart3_8_9 {
						phandle = <0xc3>;

						pin_rxd {
							bias-pull-up;
							function = "uart3";
							pins = "gpio9";
						};

						pin_txd {
							bias-disable;
							function = "uart3";
							pins = "gpio8";
						};
					};

					rp1_uart3_ctsrts_10_11 {
						phandle = <0xc4>;

						pin_cts {
							bias-pull-up;
							function = "uart3";
							pins = "gpio10";
						};

						pin_rts {
							bias-disable;
							function = "uart3";
							pins = "gpio11";
						};
					};

					rp1_uart4_12_13 {
						phandle = <0xc5>;

						pin_rxd {
							bias-pull-up;
							function = "uart4";
							pins = "gpio13";
						};

						pin_txd {
							bias-disable;
							function = "uart4";
							pins = "gpio12";
						};
					};

					rp1_uart4_ctsrts_14_15 {
						phandle = <0xc6>;

						pin_cts {
							bias-pull-up;
							function = "uart4";
							pins = "gpio14";
						};

						pin_rts {
							bias-disable;
							function = "uart4";
							pins = "gpio15";
						};
					};

					usb_vbus_pins {
						function = "vbus1";
						phandle = <0x44>;
						pins = "gpio42", "gpio43";
					};
				};

				gpiomem@d0000 {
					chardev-name = "gpiomem0";
					compatible = "raspberrypi,gpiomem";
					reg = <0xc0 0x400d0000 0x00 0x30000>;
				};

				i2c@70000 {
					clock-frequency = <0x186a0>;
					clocks = <0x02 0x0c>;
					compatible = "snps,designware-i2c";
					i2c-scl-falling-time-ns = <0x64>;
					i2c-scl-rising-time-ns = <0x41>;
					interrupts = <0x07 0x04>;
					phandle = <0x66>;
					pinctrl-0 = <0x33>;
					pinctrl-names = "default";
					reg = <0xc0 0x40070000 0x00 0x1000>;
					status = "disabled";
				};

				i2c@74000 {
					clock-frequency = <0x186a0>;
					clocks = <0x02 0x0c>;
					compatible = "snps,designware-i2c";
					i2c-scl-falling-time-ns = <0x64>;
					i2c-scl-rising-time-ns = <0x41>;
					interrupts = <0x08 0x04>;
					phandle = <0x63>;
					pinctrl-0 = <0x34>;
					pinctrl-names = "default";
					reg = <0xc0 0x40074000 0x00 0x1000>;
					status = "disabled";
				};

				i2c@78000 {
					clocks = <0x02 0x0c>;
					compatible = "snps,designware-i2c";
					i2c-scl-falling-time-ns = <0x64>;
					i2c-scl-rising-time-ns = <0x41>;
					interrupts = <0x09 0x04>;
					phandle = <0xb5>;
					pinctrl-0 = <0x35>;
					pinctrl-names = "default";
					reg = <0xc0 0x40078000 0x00 0x1000>;
					status = "disabled";
				};

				i2c@7c000 {
					clocks = <0x02 0x0c>;
					compatible = "snps,designware-i2c";
					i2c-scl-falling-time-ns = <0x64>;
					i2c-scl-rising-time-ns = <0x41>;
					interrupts = <0x0a 0x04>;
					phandle = <0xb6>;
					pinctrl-0 = <0x36>;
					pinctrl-names = "default";
					reg = <0xc0 0x4007c000 0x00 0x1000>;
					status = "disabled";
				};

				i2c@80000 {
					clock-frequency = <0x186a0>;
					clocks = <0x02 0x0c>;
					compatible = "snps,designware-i2c";
					i2c-scl-falling-time-ns = <0x64>;
					i2c-scl-rising-time-ns = <0x41>;
					interrupts = <0x0b 0x04>;
					phandle = <0x64>;
					pinctrl-0 = <0x37>;
					pinctrl-names = "default";
					reg = <0xc0 0x40080000 0x00 0x1000>;
					status = "disabled";
					symlink = "i2c-4";
				};

				i2c@84000 {
					clocks = <0x02 0x0c>;
					compatible = "snps,designware-i2c";
					i2c-scl-falling-time-ns = <0x64>;
					i2c-scl-rising-time-ns = <0x41>;
					interrupts = <0x0c 0x04>;
					phandle = <0xb7>;
					reg = <0xc0 0x40084000 0x00 0x1000>;
					status = "disabled";
				};

				i2c@88000 {
					clock-frequency = <0x186a0>;
					clocks = <0x02 0x0c>;
					compatible = "snps,designware-i2c";
					i2c-scl-falling-time-ns = <0x64>;
					i2c-scl-rising-time-ns = <0x41>;
					interrupts = <0x0d 0x04>;
					phandle = <0x65>;
					pinctrl-0 = <0x38>;
					pinctrl-names = "default";
					reg = <0xc0 0x40088000 0x00 0x1000>;
					status = "disabled";
					symlink = "i2c-6";
				};

				i2s@a0000 {
					#sound-dai-cells = <0x00>;
					clock-names = "i2sclk";
					clocks = <0x02 0x15>;
					compatible = "snps,designware-i2s";
					dma-maxburst = <0x04>;
					dma-names = "tx", "rx";
					dmas = <0x2b 0x20 0x2b 0x1f>;
					phandle = <0xba>;
					pinctrl-0 = <0x3a>;
					pinctrl-names = "default";
					reg = <0xc0 0x400a0000 0x00 0x1000>;
					status = "disabled";
				};

				i2s@a4000 {
					#sound-dai-cells = <0x00>;
					clock-names = "i2sclk";
					clocks = <0x02 0x15>;
					compatible = "snps,designware-i2s";
					dma-maxburst = <0x04>;
					dma-names = "tx", "rx";
					dmas = <0x2b 0x22 0x2b 0x21>;
					phandle = <0xbb>;
					pinctrl-0 = <0x3b>;
					pinctrl-names = "default";
					reg = <0xc0 0x400a4000 0x00 0x1000>;
					status = "disabled";
				};

				i2s@a8000 {
					clocks = <0x02 0x15>;
					compatible = "snps,designware-i2s";
					phandle = <0xbc>;
					reg = <0xc0 0x400a8000 0x00 0x1000>;
					status = "disabled";
				};

				mailbox@8000 {
					#mbox-cells = <0x01>;
					compatible = "raspberrypi,rp1-mbox";
					interrupts = <0x3a 0x04>;
					phandle = <0x5b>;
					reg = <0xc0 0x40008000 0x00 0x4000>;
					status = "okay";
				};

				mmc@180000 {
					broken-cd;
					bus-width = <0x04>;
					clock-names = "bus", "core", "timeout", "sdio";
					clocks = <0x02 0x0c 0x3d 0x02 0x1f 0x42>;
					compatible = "raspberrypi,rp1-dwcmshc";
					interrupts = <0x11 0x04>;
					no-1-8-v;
					phandle = <0xea>;
					reg = <0xc0 0x40180000 0x00 0x100>;
					status = "disabled";
					vmmc-supply = <0x3e>;
				};

				mmc@184000 {
					broken-cd;
					bus-width = <0x04>;
					clock-names = "bus", "core", "timeout", "sdio";
					clocks = <0x02 0x0c 0x3d 0x02 0x1f 0x43>;
					compatible = "raspberrypi,rp1-dwcmshc";
					interrupts = <0x12 0x04>;
					phandle = <0xeb>;
					reg = <0xc0 0x40184000 0x00 0x100>;
					sdhci-caps-mask = <0x03 0x00>;
					status = "disabled";
					vmmc-supply = <0x3e>;
				};

				pio@178000 {
					compatible = "raspberrypi,rp1-pio";
					dma-names = "tx0", "rx0", "tx1", "rx1", "tx2", "rx2", "tx3", "rx3";
					dmas = <0x2b 0x138 0x2b 0x139 0x2b 0x13a 0x2b 0x13b 0x2b 0x13c 0x2b 0x13d 0x2b 0x13e 0x2b 0x13f>;
					firmware = <0x41>;
					phandle = <0xe9>;
					reg = <0xc0 0x40178000 0x00 0x20>;
					status = "okay";
				};

				pwm@98000 {
					#pwm-cells = <0x03>;
					assigned-clock-rates = <0x2faf080>;
					assigned-clocks = <0x02 0x11>;
					clocks = <0x02 0x11>;
					compatible = "raspberrypi,rp1-pwm";
					phandle = <0xb9>;
					reg = <0xc0 0x40098000 0x00 0x100>;
					status = "disabled";
				};

				pwm@9c000 {
					#pwm-cells = <0x03>;
					assigned-clock-rates = <0x2faf080>;
					assigned-clocks = <0x02 0x12>;
					clocks = <0x02 0x12>;
					compatible = "raspberrypi,rp1-pwm";
					phandle = <0x61>;
					pinctrl-0 = <0x39>;
					pinctrl-names = "default";
					reg = <0xc0 0x4009c000 0x00 0x100>;
					status = "disabled";
				};

				sdio_clk0@b0004 {
					#clock-cells = <0x00>;
					clock-names = "src", "base";
					clocks = <0x3c 0x3d>;
					compatible = "raspberrypi,rp1-sdio-clk";
					phandle = <0x42>;
					reg = <0xc0 0x400b0004 0x00 0x1c>;
					status = "disabled";
				};

				sdio_clk1@b4004 {
					#clock-cells = <0x00>;
					clock-names = "src", "base";
					clocks = <0x3c 0x3d>;
					compatible = "raspberrypi,rp1-sdio-clk";
					phandle = <0x43>;
					reg = <0xc0 0x400b4004 0x00 0x1c>;
					status = "disabled";
				};

				serial@30000 {
					arm,primecell-periphid = <0x341011>;
					clock-names = "uartclk", "apb_pclk";
					clocks = <0x02 0x0f 0x02 0x06>;
					compatible = "arm,pl011-axi";
					cts-event-workaround;
					interrupts = <0x19 0x04>;
					phandle = <0x70>;
					pinctrl-0 = <0x2a>;
					pinctrl-names = "default";
					reg = <0xc0 0x40030000 0x00 0x100>;
					skip-init;
					status = "disabled";
					uart-has-rtscts;
				};

				serial@34000 {
					arm,primecell-periphid = <0x341011>;
					clock-names = "uartclk", "apb_pclk";
					clocks = <0x02 0x0f 0x02 0x06>;
					compatible = "arm,pl011-axi";
					cts-event-workaround;
					interrupts = <0x2a 0x04>;
					phandle = <0xa6>;
					pinctrl-names = "default";
					reg = <0xc0 0x40034000 0x00 0x100>;
					skip-init;
					status = "disabled";
					uart-has-rtscts;
				};

				serial@38000 {
					arm,primecell-periphid = <0x341011>;
					clock-names = "uartclk", "apb_pclk";
					clocks = <0x02 0x0f 0x02 0x06>;
					compatible = "arm,pl011-axi";
					cts-event-workaround;
					interrupts = <0x2b 0x04>;
					phandle = <0xa7>;
					pinctrl-names = "default";
					reg = <0xc0 0x40038000 0x00 0x100>;
					skip-init;
					status = "disabled";
					uart-has-rtscts;
				};

				serial@3c000 {
					arm,primecell-periphid = <0x341011>;
					clock-names = "uartclk", "apb_pclk";
					clocks = <0x02 0x0f 0x02 0x06>;
					compatible = "arm,pl011-axi";
					cts-event-workaround;
					interrupts = <0x2c 0x04>;
					phandle = <0xa8>;
					pinctrl-names = "default";
					reg = <0xc0 0x4003c000 0x00 0x100>;
					skip-init;
					status = "disabled";
					uart-has-rtscts;
				};

				serial@40000 {
					arm,primecell-periphid = <0x341011>;
					clock-names = "uartclk", "apb_pclk";
					clocks = <0x02 0x0f 0x02 0x06>;
					compatible = "arm,pl011-axi";
					cts-event-workaround;
					interrupts = <0x2d 0x04>;
					phandle = <0xa9>;
					pinctrl-names = "default";
					reg = <0xc0 0x40040000 0x00 0x100>;
					skip-init;
					status = "disabled";
					uart-has-rtscts;
				};

				serial@44000 {
					arm,primecell-periphid = <0x341011>;
					clock-names = "uartclk", "apb_pclk";
					clocks = <0x02 0x0f 0x02 0x06>;
					compatible = "arm,pl011-axi";
					cts-event-workaround;
					interrupts = <0x2e 0x04>;
					phandle = <0xaa>;
					pinctrl-names = "default";
					reg = <0xc0 0x40044000 0x00 0x100>;
					skip-init;
					status = "disabled";
					uart-has-rtscts;
				};

				spi@4c000 {
					#address-cells = <0x01>;
					#size-cells = <0x00>;
					clock-names = "ssi_clk";
					clocks = <0x02 0x0c>;
					compatible = "snps,dw-apb-ssi";
					dma-names = "tx", "rx";
					dmas = <0x2b 0x37 0x2b 0x36>;
					interrupts = <0x38 0x04>;
					num-cs = <0x02>;
					phandle = <0xab>;
					reg = <0xc0 0x4004c000 0x00 0x130>;
					status = "disabled";
				};

				spi@50000 {
					#address-cells = <0x01>;
					#size-cells = <0x00>;
					clock-names = "ssi_clk";
					clocks = <0x02 0x0c>;
					compatible = "snps,dw-apb-ssi";
					cs-gpios = <0x2e 0x08 0x01 0x2e 0x07 0x01>;
					dma-names = "tx", "rx";
					dmas = <0x2b 0x0d 0x2b 0x0c>;
					interrupts = <0x13 0x04>;
					num-cs = <0x02>;
					phandle = <0x6e>;
					pinctrl-0 = <0x2c 0x2d>;
					pinctrl-names = "default";
					reg = <0xc0 0x40050000 0x00 0x130>;
					status = "disabled";

					spidev@0 {
						#address-cells = <0x01>;
						#size-cells = <0x00>;
						compatible = "spidev";
						phandle = <0xac>;
						reg = <0x00>;
						spi-max-frequency = <0x7735940>;
					};

					spidev@1 {
						#address-cells = <0x01>;
						#size-cells = <0x00>;
						compatible = "spidev";
						phandle = <0xad>;
						reg = <0x01>;
						spi-max-frequency = <0x7735940>;
					};
				};

				spi@54000 {
					#address-cells = <0x01>;
					#size-cells = <0x00>;
					clock-names = "ssi_clk";
					clocks = <0x02 0x0c>;
					compatible = "snps,dw-apb-ssi";
					dma-names = "tx", "rx";
					dmas = <0x2b 0x0f 0x2b 0x0e>;
					interrupts = <0x14 0x04>;
					num-cs = <0x02>;
					phandle = <0xae>;
					reg = <0xc0 0x40054000 0x00 0x130>;
					status = "disabled";
				};

				spi@58000 {
					#address-cells = <0x01>;
					#size-cells = <0x00>;
					clock-names = "ssi_clk";
					clocks = <0x02 0x0c>;
					compatible = "snps,dw-apb-ssi";
					dma-names = "tx", "rx";
					dmas = <0x2b 0x11 0x2b 0x10>;
					interrupts = <0x15 0x04>;
					num-cs = <0x02>;
					phandle = <0xaf>;
					pinctrl-0 = <0x2f>;
					pinctrl-names = "default";
					reg = <0xc0 0x40058000 0x00 0x130>;
					status = "disabled";
				};

				spi@5c000 {
					#address-cells = <0x01>;
					#size-cells = <0x00>;
					clock-names = "ssi_clk";
					clocks = <0x02 0x0c>;
					compatible = "snps,dw-apb-ssi";
					dma-names = "tx", "rx";
					dmas = <0x2b 0x13 0x2b 0x12>;
					interrupts = <0x16 0x04>;
					num-cs = <0x02>;
					phandle = <0xb0>;
					pinctrl-0 = <0x30>;
					pinctrl-names = "default";
					reg = <0xc0 0x4005c000 0x00 0x130>;
					status = "disabled";
				};

				spi@60000 {
					#address-cells = <0x00>;
					#size-cells = <0x00>;
					clock-names = "ssi_clk";
					clocks = <0x02 0x0c>;
					compatible = "snps,dw-apb-ssi";
					dma-names = "tx", "rx";
					dmas = <0x2b 0x15 0x2b 0x14>;
					interrupts = <0x17 0x04>;
					num-cs = <0x01>;
					phandle = <0xb1>;
					pinctrl-0 = <0x31>;
					pinctrl-names = "default";
					reg = <0xc0 0x40060000 0x00 0x130>;
					spi-slave;
					status = "disabled";

					slave {
						compatible = "spidev";
						spi-max-frequency = <0xf4240>;
					};
				};

				spi@64000 {
					#address-cells = <0x01>;
					#size-cells = <0x00>;
					clock-names = "ssi_clk";
					clocks = <0x02 0x0c>;
					compatible = "snps,dw-apb-ssi";
					dma-names = "tx", "rx";
					dmas = <0x2b 0x17 0x2b 0x16>;
					interrupts = <0x18 0x04>;
					num-cs = <0x02>;
					phandle = <0xb2>;
					pinctrl-0 = <0x32>;
					pinctrl-names = "default";
					reg = <0xc0 0x40064000 0x00 0x130>;
					status = "disabled";
				};

				spi@68000 {
					#address-cells = <0x01>;
					#size-cells = <0x00>;
					clock-names = "ssi_clk";
					clocks = <0x02 0x0c>;
					compatible = "snps,dw-apb-ssi";
					dma-names = "tx", "rx";
					dmas = <0x2b 0x33 0x2b 0x32>;
					interrupts = <0x36 0x04>;
					num-cs = <0x02>;
					phandle = <0xb3>;
					reg = <0xc0 0x40068000 0x00 0x130>;
					status = "disabled";
				};

				spi@6c000 {
					#address-cells = <0x00>;
					#size-cells = <0x00>;
					clock-names = "ssi_clk";
					clocks = <0x02 0x0c>;
					compatible = "snps,dw-apb-ssi";
					dma-names = "tx", "rx";
					dmas = <0x2b 0x35 0x2b 0x34>;
					interrupts = <0x37 0x04>;
					num-cs = <0x01>;
					phandle = <0xb4>;
					reg = <0xc0 0x4006c000 0x00 0x130>;
					spi-slave;
					status = "disabled";

					slave {
						compatible = "spidev";
						spi-max-frequency = <0xf4240>;
					};
				};

				sram@400000 {
					#address-cells = <0x01>;
					#size-cells = <0x01>;
					compatible = "mmio-sram";
					phandle = <0xf2>;
					ranges = <0x00 0xc0 0x40400000 0x10000>;
					reg = <0xc0 0x40400000 0x00 0x10000>;

					shmem@ff00 {
						compatible = "raspberrypi,rp1-shmem";
						phandle = <0x5c>;
						reg = <0xff00 0x100>;
					};
				};

				usb@200000 {
					compatible = "snps,dwc3";
					dr_mode = "host";
					interrupts = <0x1f 0x01>;
					phandle = <0xec>;
					pinctrl-0 = <0x44>;
					pinctrl-names = "default";
					reg = <0xc0 0x40200000 0x00 0x100000>;
					snps,axi-pipe-limit = [08];
					snps,dis_rxdet_inp3_quirk;
					snps,enhanced-nak-fs-quirk;
					snps,parkmode-disable-fsls-quirk;
					snps,parkmode-disable-hs-quirk;
					snps,parkmode-disable-ss-quirk;
					snps,tx-max-burst = [08];
					snps,tx-thr-num-pkt = [02];
					status = "okay";
					usb3-lpm-capable;
				};

				usb@300000 {
					compatible = "snps,dwc3";
					dr_mode = "host";
					interrupts = <0x24 0x01>;
					phandle = <0xed>;
					reg = <0xc0 0x40300000 0x00 0x100000>;
					snps,axi-pipe-limit = [08];
					snps,dis_rxdet_inp3_quirk;
					snps,enhanced-nak-fs-quirk;
					snps,parkmode-disable-fsls-quirk;
					snps,parkmode-disable-hs-quirk;
					snps,parkmode-disable-ss-quirk;
					snps,tx-max-burst = [08];
					snps,tx-thr-num-pkt = [02];
					status = "okay";
					usb3-lpm-capable;
				};

				vec@144000 {
					assigned-clock-parents = <0x00 0x02 0x02 0x02 0x0b>;
					assigned-clock-rates = <0x46cf7100 0x66ff300 0x66ff300>;
					assigned-clocks = <0x02 0x02 0x02 0x0b 0x02 0x27>;
					clocks = <0x02 0x27>;
					compatible = "raspberrypi,rp1vec";
					interrupts = <0x31 0x04>;
					iommus = <0x40>;
					phandle = <0xf0>;
					reg = <0xc0 0x40144000 0x00 0x1000 0xc0 0x40140000 0x00 0x1000>;
					status = "disabled";
				};
			};
		};

		pisp_be@880000 {
			clocks = <0x17 0x07>;
			clocks-names = "isp_be";
			compatible = "raspberrypi,pispbe";
			interrupts = <0x00 0x48 0x04>;
			iommus = <0x49>;
			phandle = <0xf7>;
			reg = <0x10 0x880000 0x00 0x4000>;
			status = "okay";
		};

		syscon@400018 {
			compatible = "brcm,syscon-piarbctl", "syscon", "simple-mfd";
			phandle = <0xf4>;
			reg = <0x10 0x400018 0x00 0x18>;
		};

		usb@480000 {
			#address-cells = <0x01>;
			#size-cells = <0x00>;
			clock-names = "otg";
			clocks = <0x46>;
			compatible = "brcm,bcm2835-usb";
			interrupts = <0x00 0x49 0x04>;
			phandle = <0xf5>;
			phy-names = "usb2-phy";
			phys = <0x47>;
			power-domains = <0x48 0x06>;
			reg = <0x10 0x480000 0x00 0x10000>;
			status = "disabled";
		};

		v3d@2000000 {
			clocks = <0x17 0x05>;
			clocks-names = "v3d";
			compatible = "brcm,2712-v3d";
			interrupts = <0x00 0xfa 0x04 0x00 0xf9 0x04>;
			phandle = <0xf9>;
			power-domains = <0x4c 0x01>;
			reg = <0x10 0x2000000 0x00 0x4000 0x10 0x2008000 0x00 0x6000 0x10 0x2030800 0x00 0x700>;
			reg-names = "hub", "core0", "sms";
			resets = <0x4c 0x00>;
			status = "disabled";
		};
	};

	cam0_clk {
		#clock-cells = <0x00>;
		compatible = "fixed-clock";
		phandle = <0x101>;
		status = "disabled";
	};

	cam0_reg {
		compatible = "regulator-fixed";
		enable-active-high;
		gpio = <0x2e 0x22 0x00>;
		phandle = <0x72>;
		regulator-name = "cam0_reg";
	};

	cam1_clk {
		#clock-cells = <0x00>;
		compatible = "fixed-clock";
		phandle = <0x100>;
		status = "disabled";
	};

	cam1_reg {
		compatible = "regulator-fixed";
		enable-active-high;
		gpio = <0x2e 0x2e 0x00>;
		phandle = <0x73>;
		regulator-name = "cam1_reg";
	};

	cam_dummy_reg {
		compatible = "regulator-fixed";
		phandle = <0x102>;
		regulator-name = "cam-dummy-reg";
	};

	chosen {
		bootargs = "reboot=w coherent_pool=1M 8250.nr_uarts=1 pci=pcie_bus_safe cgroup_disable=memory numa_policy=interleave nvme.max_host_mem_size_mb=0";
		phandle = <0x6f>;
		stdout-path = "serial10:115200n8";
	};

	clk-108M {
		#clock-cells = <0x00>;
		clock-frequency = <0x66ff300>;
		clock-output-names = "108MHz-clock";
		compatible = "fixed-clock";
		phandle = <0x11>;
	};

	clk-27M {
		#clock-cells = <0x00>;
		clock-frequency = <0x19bfcc0>;
		clock-output-names = "27MHz-clock";
		compatible = "fixed-clock";
		phandle = <0x18>;
	};

	clocks {
		#address-cells = <0x01>;
		#size-cells = <0x00>;
		compatible = "simple-bus";
		phandle = <0x76>;

		clk-emmc2 {
			#clock-cells = <0x00>;
			clock-frequency = <0xbebc200>;
			clock-output-names = "emmc2-clock";
			compatible = "fixed-clock";
			phandle = <0x08>;
		};

		clk-osc {
			#clock-cells = <0x00>;
			clock-frequency = <0x337f980>;
			clock-output-names = "osc";
			compatible = "fixed-clock";
			phandle = <0x77>;
		};

		clk-uart {
			#clock-cells = <0x00>;
			clock-frequency = <0x8ca000>;
			clock-output-names = "uart-clock";
			compatible = "fixed-clock";
			phandle = <0x0e>;
		};

		clk-usb {
			#clock-cells = <0x00>;
			clock-frequency = <0x1c9c3800>;
			clock-output-names = "otg";
			compatible = "fixed-clock";
			phandle = <0x46>;
		};

		clk-vpu {
			#clock-cells = <0x00>;
			clock-frequency = <0x2cb41780>;
			clock-output-names = "vpu-clock";
			compatible = "fixed-clock";
			phandle = <0x0f>;
		};

		clk_xosc {
			#clock-cells = <0x00>;
			clock-frequency = <0x2faf080>;
			clock-output-names = "xosc";
			compatible = "fixed-clock";
			phandle = <0x29>;
		};

		clksrc_gp0 {
			#clock-cells = <0x00>;
			clock-div = <0x01>;
			clock-mult = <0x01>;
			clock-output-names = "clksrc_gp0";
			clocks = <0x02 0x21>;
			compatible = "fixed-factor-clock";
			phandle = <0x78>;
			status = "disabled";
		};

		clksrc_gp1 {
			#clock-cells = <0x00>;
			clock-div = <0x01>;
			clock-mult = <0x01>;
			clock-output-names = "clksrc_gp1";
			clocks = <0x02 0x22>;
			compatible = "fixed-factor-clock";
			phandle = <0x79>;
			status = "disabled";
		};

		clksrc_gp2 {
			#clock-cells = <0x00>;
			clock-div = <0x01>;
			clock-mult = <0x01>;
			clock-output-names = "clksrc_gp2";
			clocks = <0x02 0x23>;
			compatible = "fixed-factor-clock";
			phandle = <0x7a>;
			status = "disabled";
		};

		clksrc_gp3 {
			#clock-cells = <0x00>;
			clock-div = <0x01>;
			clock-mult = <0x01>;
			clock-output-names = "clksrc_gp3";
			clocks = <0x02 0x24>;
			compatible = "fixed-factor-clock";
			phandle = <0x7b>;
			status = "disabled";
		};

		clksrc_gp4 {
			#clock-cells = <0x00>;
			clock-div = <0x01>;
			clock-mult = <0x01>;
			clock-output-names = "clksrc_gp4";
			clocks = <0x02 0x25>;
			compatible = "fixed-factor-clock";
			phandle = <0x7c>;
			status = "disabled";
		};

		clksrc_gp5 {
			#clock-cells = <0x00>;
			clock-div = <0x01>;
			clock-mult = <0x01>;
			clock-output-names = "clksrc_gp5";
			clocks = <0x02 0x26>;
			compatible = "fixed-factor-clock";
			phandle = <0x7d>;
			status = "disabled";
		};

		sdhci_core {
			#clock-cells = <0x00>;
			clock-frequency = <0x2faf080>;
			clock-output-names = "core";
			compatible = "fixed-clock";
			phandle = <0x3d>;
		};

		sdio_src {
			#clock-cells = <0x00>;
			clock-frequency = <0x3b9aca00>;
			clock-output-names = "src";
			compatible = "fixed-clock";
			phandle = <0x3c>;
		};
	};

	cooling_fan {
		#cooling-cells = <0x02>;
		compatible = "pwm-fan";
		cooling-levels = <0x00 0x4b 0x7d 0xaf 0xfa>;
		cooling-max-state = <0x03>;
		cooling-min-state = <0x00>;
		phandle = <0x54>;
		pwms = <0x61 0x03 0xa25e 0x01>;
		rpm-offset = <0x3c>;
		rpm-regmap = <0x61>;
		status = "disabled";
	};

	cpus {
		#address-cells = <0x01>;
		#size-cells = <0x00>;
		phandle = <0x7e>;

		cpu@0 {
			compatible = "arm,cortex-a76";
			d-cache-line-size = <0x40>;
			d-cache-sets = <0x100>;
			d-cache-size = <0x10000>;
			device_type = "cpu";
			enable-method = "psci";
			i-cache-line-size = <0x40>;
			i-cache-sets = <0x100>;
			i-cache-size = <0x10000>;
			next-level-cache = <0x03>;
			phandle = <0x4e>;
			reg = <0x00>;

			l2-cache-l0 {
				cache-level = <0x02>;
				cache-line-size = <0x40>;
				cache-sets = <0x400>;
				cache-size = <0x80000>;
				cache-unified;
				compatible = "cache";
				next-level-cache = <0x04>;
				phandle = <0x03>;
			};
		};

		cpu@1 {
			compatible = "arm,cortex-a76";
			d-cache-line-size = <0x40>;
			d-cache-sets = <0x100>;
			d-cache-size = <0x10000>;
			device_type = "cpu";
			enable-method = "psci";
			i-cache-line-size = <0x40>;
			i-cache-sets = <0x100>;
			i-cache-size = <0x10000>;
			next-level-cache = <0x05>;
			phandle = <0x4f>;
			reg = <0x100>;

			l2-cache-l1 {
				cache-level = <0x02>;
				cache-line-size = <0x40>;
				cache-sets = <0x400>;
				cache-size = <0x80000>;
				cache-unified;
				compatible = "cache";
				next-level-cache = <0x04>;
				phandle = <0x05>;
			};
		};

		cpu@2 {
			compatible = "arm,cortex-a76";
			d-cache-line-size = <0x40>;
			d-cache-sets = <0x100>;
			d-cache-size = <0x10000>;
			device_type = "cpu";
			enable-method = "psci";
			i-cache-line-size = <0x40>;
			i-cache-sets = <0x100>;
			i-cache-size = <0x10000>;
			next-level-cache = <0x06>;
			phandle = <0x50>;
			reg = <0x200>;

			l2-cache-l2 {
				cache-level = <0x02>;
				cache-line-size = <0x40>;
				cache-sets = <0x400>;
				cache-size = <0x80000>;
				cache-unified;
				compatible = "cache";
				next-level-cache = <0x04>;
				phandle = <0x06>;
			};
		};

		cpu@3 {
			compatible = "arm,cortex-a76";
			d-cache-line-size = <0x40>;
			d-cache-sets = <0x100>;
			d-cache-size = <0x10000>;
			device_type = "cpu";
			enable-method = "psci";
			i-cache-line-size = <0x40>;
			i-cache-sets = <0x100>;
			i-cache-size = <0x10000>;
			next-level-cache = <0x07>;
			phandle = <0x51>;
			reg = <0x300>;

			l2-cache-l3 {
				cache-level = <0x02>;
				cache-line-size = <0x40>;
				cache-sets = <0x400>;
				cache-size = <0x80000>;
				cache-unified;
				compatible = "cache";
				next-level-cache = <0x04>;
				phandle = <0x07>;
			};
		};

		l3-cache {
			cache-level = <0x03>;
			cache-line-size = <0x40>;
			cache-sets = <0x800>;
			cache-size = <0x200000>;
			cache-unified;
			compatible = "cache";
			phandle = <0x04>;
		};
	};

	dummy {
		phandle = <0x103>;
	};

	firmwarekms {
		brcm,firmware = <0x1a>;
		compatible = "raspberrypi,rpi-firmware-kms-2712";
		interrupt-parent = <0x59>;
		interrupts = <0x13>;
		phandle = <0xfe>;
		status = "disabled";
	};

	hvs@107c580000 {
		clock-names = "core", "disp";
		clocks = <0x17 0x04 0x17 0x10>;
		compatible = "brcm,bcm2712-hvs";
		interrupt-names = "ch0-eof", "ch1-eof", "ch2-eof";
		interrupt-parent = <0x10>;
		interrupts = <0x02 0x09 0x10>;
		iommus = <0x4d>;
		phandle = <0xfa>;
		reg = <0x10 0x7c580000 0x1a000>;
		status = "disabled";
	};

	i2c0if {
		phandle = <0x104>;
	};

	i2c0mux {
		phandle = <0x105>;
	};

	leds {
		compatible = "gpio-leds";
		phandle = <0xff>;

		led-act {
			default-state = "off";
			gpios = <0x0d 0x09 0x01>;
			label = "ACT";
			linux,default-trigger = "mmc0";
			phandle = <0x5d>;
		};

		led-pwr {
			default-state = "off";
			gpios = <0x2e 0x2c 0x01>;
			label = "PWR";
			linux,default-trigger = "none";
			phandle = <0x6b>;
		};
	};

	memory@0 {
		device_type = "memory";
		reg = <0x00 0x00 0x28000000>;
	};

	phy {
		#phy-cells = <0x00>;
		compatible = "usb-nop-xceiv";
		phandle = <0x47>;
	};

	psci {
		compatible = "arm,psci-1.0", "arm,psci-0.2";
		method = "smc";
	};

	pwr_button {
		compatible = "gpio-keys";
		pinctrl-0 = <0x75>;
		pinctrl-names = "default";
		status = "okay";

		pwr {
			debounce-interval = <0x32>;
			gpios = <0x1b 0x14 0x01>;
			label = "pwr_button";
			linux,code = <0x74>;
			phandle = <0x60>;
		};
	};

	reserved-memory {
		#address-cells = <0x02>;
		#size-cells = <0x01>;
		phandle = <0x7f>;
		ranges;

		atf@0 {
			no-map;
			reg = <0x00 0x00 0x80000>;
		};

		linux,cma {
			alloc-ranges = <0x00 0x00 0x40000000>;
			compatible = "shared-dma-pool";
			linux,cma-default;
			phandle = <0x80>;
			reusable;
			size = <0x4000000>;
		};

		nvram@0 {
			#address-cells = <0x01>;
			#size-cells = <0x01>;
			compatible = "raspberrypi,bootloader-config", "nvmem-rmem";
			no-map;
			phandle = <0x81>;
			reg = <0x00 0x00 0x00>;
			status = "disabled";
		};

		nvram@1 {
			#address-cells = <0x01>;
			#size-cells = <0x01>;
			compatible = "raspberrypi,bootloader-public-key", "nvmem-rmem";
			no-map;
			phandle = <0x82>;
			reg = <0x00 0x00 0x00>;
			status = "disabled";
		};
	};

	rp1_firmware {
		compatible = "raspberrypi,rp1-firmware", "simple-mfd";
		mboxes = <0x5b 0x00>;
		phandle = <0x41>;
		shmem = <0x5c>;
	};

	rp1_vdd_3v3 {
		compatible = "regulator-fixed";
		phandle = <0x3e>;
		regulator-always-on;
		regulator-max-microvolt = <0x325aa0>;
		regulator-min-microvolt = <0x325aa0>;
		regulator-name = "vdd-3v3";
	};

	sd-io-1v8-reg {
		compatible = "regulator-gpio";
		gpios = <0x0d 0x03 0x00>;
		phandle = <0x0b>;
		regulator-always-on;
		regulator-boot-on;
		regulator-max-microvolt = <0x325aa0>;
		regulator-min-microvolt = <0x1b7740>;
		regulator-name = "vdd-sd-io";
		regulator-settling-time-us = <0x1388>;
		states = <0x1b7740 0x01 0x325aa0 0x00>;
	};

	sd-vcc-reg {
		compatible = "regulator-fixed";
		enable-active-high;
		gpios = <0x0d 0x04 0x00>;
		phandle = <0x0c>;
		regulator-boot-on;
		regulator-max-microvolt = <0x325aa0>;
		regulator-min-microvolt = <0x325aa0>;
		regulator-name = "vcc-sd";
	};

	soc@107c000000 {
		#address-cells = <0x01>;
		#size-cells = <0x01>;
		compatible = "simple-bus";
		phandle = <0x83>;
		ranges = <0x00 0x10 0x00 0x80000000>;

		avs-monitor@7d542000 {
			compatible = "brcm,bcm2711-avs-monitor", "syscon", "simple-mfd";
			phandle = <0x9b>;
			reg = <0x7d542000 0xf00>;
			status = "okay";

			thermal {
				#thermal-sensor-cells = <0x00>;
				compatible = "brcm,bcm2711-thermal";
				phandle = <0x52>;
			};
		};

		axiperf@7c012800 {
			compatible = "brcm,bcm2712-axiperf";
			firmware = <0x1a>;
			phandle = <0x5e>;
			reg = <0x7c012800 0x100 0x7e000000 0x100>;
			status = "disabled";
		};

		clock@7c700000 {
			#clock-cells = <0x01>;
			#reset-cells = <0x01>;
			clocks = <0x11>;
			compatible = "brcm,brcm2711-dvp";
			phandle = <0x13>;
			reg = <0x7c700000 0x10>;
		};

		fb {
			compatible = "brcm,bcm2708-fb";
			firmware = <0x1a>;
			phandle = <0x9e>;
		};

		firmware {
			#address-cells = <0x01>;
			#size-cells = <0x01>;
			compatible = "raspberrypi,bcm2835-firmware", "simple-mfd";
			dma-ranges;
			mboxes = <0x22>;
			phandle = <0x1a>;

			clocks {
				#clock-cells = <0x01>;
				compatible = "raspberrypi,firmware-clocks";
				phandle = <0x17>;
			};

			reset {
				#reset-cells = <0x01>;
				compatible = "raspberrypi,firmware-reset";
				phandle = <0x9c>;
			};

			vcio {
				compatible = "raspberrypi,vcio";
				phandle = <0x9d>;
			};
		};

		fixedregulator_3v3 {
			compatible = "regulator-fixed";
			phandle = <0xa0>;
			regulator-always-on;
			regulator-max-microvolt = <0x325aa0>;
			regulator-min-microvolt = <0x325aa0>;
			regulator-name = "3v3";
		};

		fixedregulator_5v0 {
			compatible = "regulator-fixed";
			phandle = <0xa1>;
			regulator-always-on;
			regulator-max-microvolt = <0x4c4b40>;
			regulator-min-microvolt = <0x4c4b40>;
			regulator-name = "5v0";
		};

		gpio@7d508500 {
			#gpio-cells = <0x02>;
			#interrupt-cells = <0x02>;
			brcm,gpio-bank-widths = <0x20 0x04>;
			brcm,gpio-direct;
			compatible = "brcm,brcmstb-gpio";
			gpio-controller;
			gpio-line-names = "-", "2712_BOOT_CS_N", "2712_BOOT_MISO", "2712_BOOT_MOSI", "2712_BOOT_SCLK", "-", "-", "-", "-", "-", "-", "-", "-", "-", "PCIE_SDA", "PCIE_SCL", "-", "-", "-", "-", "PWR_GPIO", "2712_G21_FS", "-", "-", "BT_RTS", "BT_CTS", "BT_TXD", "BT_RXD", "WL_ON", "BT_ON", "WIFI_SDIO_CLK", "WIFI_SDIO_CMD", "WIFI_SDIO_D0", "WIFI_SDIO_D1", "WIFI_SDIO_D2", "WIFI_SDIO_D3";
			interrupt-controller;
			interrupt-parent = <0x1f>;
			interrupts = <0x00>;
			phandle = <0x1b>;
			reg = <0x7d508500 0x40>;
		};

		gpio@7d517c00 {
			#gpio-cells = <0x02>;
			brcm,gpio-bank-widths = <0x11 0x06>;
			brcm,gpio-direct;
			compatible = "brcm,brcmstb-gpio";
			gpio-controller;
			gpio-line-names = "RP1_SDA", "RP1_SCL", "RP1_RUN", "SD_IOVDD_SEL", "SD_PWR_ON", "SD_CDET_N", "SD_FLG_N", "-", "2712_WAKE", "2712_STAT_LED", "-", "-", "PMIC_INT", "UART_TX_FS", "UART_RX_FS", "-", "-", "", "", "", "", "", "", "", "", "", "", "", "", "", "", "", "HDMI0_SCL", "HDMI0_SDA", "HDMI1_SCL", "HDMI1_SDA", "PMIC_SCL", "PMIC_SDA";
			phandle = <0x0d>;
			reg = <0x7d517c00 0x40>;

			rp1_run_hog {
				gpio-hog;
				gpios = <0x02 0x00>;
				line-name = "RP1 RUN pin";
				output-high;
			};
		};

		gpiomem@7d504100 {
			chardev-name = "gpiomem3";
			compatible = "raspberrypi,gpiomem";
			reg = <0x7d504100 0x20>;
		};

		gpiomem@7d508500 {
			chardev-name = "gpiomem1";
			compatible = "raspberrypi,gpiomem";
			reg = <0x7d508500 0x40>;
		};

		gpiomem@7d510700 {
			chardev-name = "gpiomem4";
			compatible = "raspberrypi,gpiomem";
			reg = <0x7d510700 0x20>;
		};

		gpiomem@7d517c00 {
			chardev-name = "gpiomem2";
			compatible = "raspberrypi,gpiomem";
			reg = <0x7d517c00 0x40>;
		};

		hdmi@7ef00700 {
			clock-names = "hdmi", "bvb", "audio", "cec";
			clocks = <0x17 0x0d 0x17 0x0e 0x13 0x00 0x18>;
			compatible = "brcm,bcm2712-hdmi0";
			ddc = <0x15>;
			dma-names = "audio-rx";
			dmas = <0x16 0x41fa000a>;
			interrupt-names = "cec-tx", "cec-rx", "cec-low", "hpd-connected", "hpd-removed";
			interrupt-parent = <0x14>;
			interrupts = <0x01 0x02 0x03 0x07 0x08>;
			phandle = <0x8b>;
			reg = <0x7c701400 0x300 0x7c701000 0x200 0x7c701d00 0x300 0x7c702000 0x80 0x7c703800 0x200 0x7c704000 0x800 0x7c700100 0x80 0x7d510800 0x100 0x7c720000 0x100>;
			reg-names = "hdmi", "dvp", "phy", "rm", "packet", "metadata", "csc", "cec", "hd";
			resets = <0x13 0x01>;
			status = "disabled";
		};

		hdmi@7ef05700 {
			clock-names = "hdmi", "bvb", "audio", "cec";
			clocks = <0x17 0x0d 0x17 0x0e 0x13 0x01 0x18>;
			compatible = "brcm,bcm2712-hdmi1";
			ddc = <0x19>;
			dma-names = "audio-rx";
			dmas = <0x16 0x41fa0011>;
			interrupt-names = "cec-tx", "cec-rx", "cec-low", "hpd-connected", "hpd-removed";
			interrupt-parent = <0x14>;
			interrupts = <0x0b 0x0c 0x0d 0x0e 0x0f>;
			phandle = <0x8c>;
			reg = <0x7c706400 0x300 0x7c706000 0x200 0x7c706d00 0x300 0x7c707000 0x80 0x7c708800 0x200 0x7c709000 0x800 0x7c700180 0x80 0x7d511000 0x100 0x7c720000 0x100>;
			reg-names = "hdmi", "dvp", "phy", "rm", "packet", "metadata", "csc", "cec", "hd";
			resets = <0x13 0x02>;
			status = "disabled";
		};

		i2c@7d005600 {
			#address-cells = <0x01>;
			#size-cells = <0x00>;
			clock-frequency = <0x61a80>;
			clocks = <0x0f>;
			compatible = "brcm,bcm2711-i2c", "brcm,bcm2835-i2c";
			interrupts = <0x00 0x75 0x04>;
			phandle = <0x8f>;
			pinctrl-0 = <0x1e>;
			pinctrl-names = "default";
			reg = <0x7d005600 0x20>;
			status = "disabled";
		};

		i2c@7d508200 {
			#address-cells = <0x01>;
			#size-cells = <0x00>;
			clock-frequency = <0x17cdc>;
			compatible = "brcm,brcmstb-i2c";
			interrupt-parent = <0x12>;
			interrupts = <0x01>;
			phandle = <0x15>;
			reg = <0x7d508200 0x58>;
			status = "disabled";
		};

		i2c@7d508280 {
			#address-cells = <0x01>;
			#size-cells = <0x00>;
			clock-frequency = <0x17cdc>;
			compatible = "brcm,brcmstb-i2c";
			interrupt-parent = <0x12>;
			interrupts = <0x02>;
			phandle = <0x19>;
			reg = <0x7d508280 0x58>;
			status = "disabled";
		};

		intc@7d503000 {
			#interrupt-cells = <0x01>;
			compatible = "brcm,l2-intc";
			interrupt-controller;
			interrupts = <0x00 0xee 0x04>;
			phandle = <0x59>;
			reg = <0x7d503000 0x18>;
		};

		intc@7d508380 {
			#interrupt-cells = <0x01>;
			compatible = "brcm,bcm7271-l2-intc";
			interrupt-controller;
			interrupts = <0x00 0xf2 0x04>;
			phandle = <0x12>;
			reg = <0x7d508380 0x10>;
		};

		intc@7d508400 {
			#interrupt-cells = <0x01>;
			compatible = "brcm,bcm7271-l2-intc";
			interrupt-controller;
			interrupts = <0x00 0xf4 0x04>;
			phandle = <0x1f>;
			reg = <0x7d508400 0x10>;
		};

		intc@7d517ac0 {
			#interrupt-cells = <0x01>;
			compatible = "brcm,bcm7271-l2-intc";
			interrupt-controller;
			interrupts = <0x00 0xf5 0x04>;
			phandle = <0x9a>;
			reg = <0x7d517ac0 0x10>;
			status = "disabled";
		};

		interrupt-controller@7c502000 {
			#interrupt-cells = <0x01>;
			compatible = "brcm,bcm2711-l2-intc", "brcm,l2-intc";
			interrupt-controller;
			interrupts = <0x00 0x61 0x04>;
			phandle = <0x10>;
			reg = <0x7c502000 0x30>;
			status = "disabled";
		};

		interrupt-controller@7cd00000 {
			compatible = "brcm,bcm2836-l1-intc";
			phandle = <0x85>;
			reg = <0x7cd00000 0x100>;
		};

		interrupt-controller@7d510600 {
			#interrupt-cells = <0x01>;
			compatible = "brcm,bcm2711-l2-intc", "brcm,l2-intc";
			interrupt-controller;
			interrupts = <0x00 0xef 0x04>;
			phandle = <0x14>;
			reg = <0x7d510600 0x30>;
			status = "disabled";
		};

		interrupt-controller@7d517000 {
			#interrupt-cells = <0x01>;
			compatible = "brcm,bcm7271-l2-intc";
			interrupt-controller;
			interrupts = <0x00 0xf7 0x04>;
			reg = <0x7d517000 0x10>;
			status = "disabled";
		};

		interrupt-controller@7fff9000 {
			#interrupt-cells = <0x03>;
			compatible = "arm,gic-400";
			interrupt-controller;
			interrupts = <0x01 0x09 0xf04>;
			phandle = <0x01>;
			reg = <0x7fff9000 0x1000 0x7fffa000 0x2000 0x7fffc000 0x2000 0x7fffe000 0x2000>;
		};

		mailbox@7c013880 {
			#mbox-cells = <0x00>;
			compatible = "brcm,bcm2835-mbox";
			interrupts = <0x00 0x21 0x04>;
			phandle = <0x22>;
			reg = <0x7c013880 0x40>;
		};

		mmc@fff000 {
			bus-width = <0x04>;
			cd-gpios = <0x0d 0x05 0x01>;
			clock-names = "sw_sdio";
			clocks = <0x08>;
			compatible = "brcm,bcm2712-sdhci", "brcm,sdhci-brcmstb";
			interrupts = <0x00 0x111 0x04>;
			mmc-ddr-3_3v;
			phandle = <0x74>;
			pinctrl-0 = <0x09 0x0a>;
			pinctrl-names = "default";
			reg = <0xfff000 0x260 0xfff400 0x200>;
			reg-names = "host", "cfg";
			sd-uhs-ddr50;
			sd-uhs-sdr104;
			sd-uhs-sdr50;
			status = "okay";
			supports-cqe = <0x01>;
			vmmc-supply = <0x0c>;
			vqmmc-supply = <0x0b>;
		};

		mop@7c500000 {
			compatible = "brcm,bcm2712-mop";
			interrupt-parent = <0x10>;
			interrupts = <0x01>;
			phandle = <0x89>;
			reg = <0x7c500000 0x28>;
			status = "disabled";
		};

		moplet@7c501000 {
			compatible = "brcm,bcm2712-moplet";
			interrupt-parent = <0x10>;
			interrupts = <0x00>;
			phandle = <0x8a>;
			reg = <0x7c501000 0x20>;
			status = "disabled";
		};

		nvmem {
			#address-cells = <0x01>;
			#size-cells = <0x01>;
			compatible = "simple-bus";

			nvmem_cust {
				compatible = "raspberrypi,rpi-otp";
				firmware = <0x1a>;
				phandle = <0x68>;
				reg = <0x01 0x08>;
			};

			nvmem_mac {
				compatible = "raspberrypi,rpi-otp";
				firmware = <0x1a>;
				phandle = <0x69>;
				reg = <0x02 0x06>;
			};

			nvmem_otp {
				compatible = "raspberrypi,rpi-otp";
				firmware = <0x1a>;
				phandle = <0x9f>;
				reg = <0x00 0xc0>;
			};

			nvmem_priv {
				compatible = "raspberrypi,rpi-otp";
				firmware = <0x1a>;
				phandle = <0x6a>;
				reg = <0x03 0x10>;
			};
		};

		pinctrl@7d504100 {
			compatible = "brcm,bcm2712-pinctrl";
			phandle = <0x90>;
			reg = <0x7d504100 0x30>;

			bt_shutdown_pins {
				function = "gpio";
				phandle = <0x21>;
				pins = "gpio29";
			};

			emmc_sd_pulls {
				bias-pull-up;
				phandle = <0x09>;
				pins = "emmc_cmd", "emmc_dat0", "emmc_dat1", "emmc_dat2", "emmc_dat3";
			};

			pwr_button_pins {
				bias-pull-up;
				function = "gpio";
				phandle = <0x75>;
				pins = "gpio20";
			};

			sdio2_30_pins {
				phandle = <0x4a>;

				pin_clk {
					bias-disable;
					function = "sd2";
					pins = "gpio30";
				};

				pin_cmd {
					bias-pull-up;
					function = "sd2";
					pins = "gpio31";
				};

				pins_dat {
					bias-pull-up;
					function = "sd2";
					pins = "gpio32", "gpio33", "gpio34", "gpio35";
				};
			};

			spi10_cs_gpio1 {
				bias-pull-up;
				function = "gpio";
				phandle = <0x1d>;
				pins = "gpio1";
			};

			spi10_gpio2 {
				bias-disable;
				function = "vc_spi0";
				phandle = <0x1c>;
				pins = "gpio2", "gpio3", "gpio4";
			};

			uarta_24_pins {
				phandle = <0x20>;

				pin_cts {
					bias-pull-up;
					function = "uart0";
					pins = "gpio25";
				};

				pin_rts {
					bias-disable;
					function = "uart0";
					pins = "gpio24";
				};

				pin_rxd {
					bias-pull-up;
					function = "uart0";
					pins = "gpio27";
				};

				pin_txd {
					bias-disable;
					function = "uart0";
					pins = "gpio26";
				};
			};

			wl_on_pins {
				function = "gpio";
				phandle = <0x5a>;
				pins = "gpio28";
			};
		};

		pinctrl@7d510700 {
			compatible = "brcm,bcm2712-aon-pinctrl";
			phandle = <0x92>;
			reg = <0x7d510700 0x20>;

			aon_pwm_1pin {
				function = "aon_pwm";
				phandle = <0x99>;
				pins = "aon_gpio9";
			};

			bsc_m1_agpio13_pins {
				bias-pull-up;
				function = "bsc_m1";
				phandle = <0x93>;
				pins = "aon_gpio13", "aon_gpio14";
			};

			bsc_m2_sgpio4_pins {
				function = "bsc_m2";
				phandle = <0x95>;
				pins = "aon_sgpio4", "aon_sgpio5";
			};

			bsc_pmu_sgpio4_pins {
				function = "avs_pmu_bsc";
				phandle = <0x94>;
				pins = "aon_sgpio4", "aon_sgpio5";
			};

			emmc_aon_cd_pins {
				bias-pull-up;
				function = "sd_card_g";
				phandle = <0x0a>;
				pins = "aon_gpio5";
			};

			i2c3_m4_agpio0_pins {
				bias-pull-up;
				function = "vc_i2c3";
				phandle = <0x1e>;
				pins = "aon_gpio0", "aon_gpio1";
			};

			pwm_aon_agpio1_pins {
				function = "aon_pwm";
				phandle = <0x96>;
				pins = "aon_gpio1", "aon_gpio2";
			};

			pwm_aon_agpio4_pins {
				function = "vc_pwm0";
				phandle = <0x97>;
				pins = "aon_gpio4", "aon_gpio5";
			};

			pwm_aon_agpio7_pins {
				function = "aon_pwm";
				phandle = <0x98>;
				pins = "aon_gpio7", "aon_gpio9";
			};
		};

		pixelvalve@7c410000 {
			compatible = "brcm,bcm2712-pixelvalve0";
			interrupts = <0x00 0x65 0x04>;
			phandle = <0x87>;
			reg = <0x7c410000 0x100>;
			status = "disabled";
		};

		pixelvalve@7c411000 {
			compatible = "brcm,bcm2712-pixelvalve1";
			interrupts = <0x00 0x6e 0x04>;
			phandle = <0x88>;
			reg = <0x7c411000 0x100>;
			status = "disabled";
		};

		power {
			#power-domain-cells = <0x01>;
			compatible = "raspberrypi,bcm2835-power";
			firmware = <0x1a>;
			phandle = <0x48>;
		};

		reset-controller@119500 {
			#reset-cells = <0x00>;
			compatible = "brcm,bcm7216-pcie-sata-rescal";
			phandle = <0x23>;
			reg = <0x119500 0x10>;
		};

		reset-controller@1504318 {
			#reset-cells = <0x01>;
			compatible = "brcm,brcmstb-reset";
			phandle = <0x24>;
			reg = <0x1504318 0x30>;
		};

		rng@7d208000 {
			compatible = "brcm,bcm2711-rng200";
			phandle = <0x6c>;
			reg = <0x7d208000 0x28>;
			status = "okay";
		};

		rpi_rtc {
			compatible = "raspberrypi,rpi-rtc";
			firmware = <0x1a>;
			phandle = <0x6d>;
			trickle-charge-microvolt = <0x00>;
		};

		serial@7d001000 {
			arm,primecell-periphid = <0x341011>;
			clock-names = "uartclk", "apb_pclk";
			clocks = <0x0e 0x0f>;
			compatible = "arm,pl011", "arm,primecell";
			interrupts = <0x00 0x79 0x04>;
			phandle = <0x86>;
			reg = <0x7d001000 0x200>;
			status = "okay";
		};

		serial@7d50c000 {
			auto-flow-control;
			clock-frequency = <0x5b8d800>;
			compatible = "brcm,bcm7271-uart";
			interrupts = <0x00 0x114 0x04>;
			phandle = <0x91>;
			pinctrl-0 = <0x20 0x21>;
			pinctrl-names = "default";
			reg = <0x7d50c000 0x20>;
			reg-io-width = <0x04>;
			reg-names = "uart";
			reg-shift = <0x02>;
			skip-init;
			status = "okay";
			uart-has-rtscts;

			bluetooth {
				compatible = "brcm,bcm43438-bt";
				local-bd-address = [00 00 00 00 00 00];
				max-speed = <0x2dc6c0>;
				phandle = <0x5f>;
				shutdown-gpios = <0x1b 0x1d 0x00>;
			};
		};

		sound {
			phandle = <0xa2>;
			status = "disabled";
		};

		spi@7d004000 {
			#address-cells = <0x01>;
			#size-cells = <0x00>;
			clocks = <0x0f>;
			compatible = "brcm,bcm2835-spi";
			cs-gpios = <0x1b 0x01 0x01>;
			dma-names = "tx", "rx";
			dmas = <0x16 0x06 0x16 0x07>;
			interrupts = <0x00 0x76 0x04>;
			num-cs = <0x01>;
			phandle = <0x8d>;
			pinctrl-0 = <0x1c 0x1d>;
			pinctrl-names = "default";
			reg = <0x7d004000 0x200>;
			status = "okay";

			spidev@0 {
				#address-cells = <0x01>;
				#size-cells = <0x00>;
				compatible = "spidev";
				phandle = <0x8e>;
				reg = <0x00>;
				spi-max-frequency = <0x1312d00>;
				status = "okay";
			};
		};

		timer@7c003000 {
			clock-frequency = <0xf4240>;
			compatible = "brcm,bcm2835-system-timer";
			interrupts = <0x00 0x40 0x04 0x00 0x41 0x04 0x00 0x42 0x04 0x00 0x43 0x04>;
			phandle = <0x84>;
			reg = <0x7c003000 0x1000>;
		};

		watchdog@7d200000 {
			#power-domain-cells = <0x01>;
			#reset-cells = <0x01>;
			compatible = "brcm,bcm2712-pm";
			phandle = <0x4c>;
			reg = <0x7d200000 0x308>;
			reg-names = "pm";
			system-power-controller;
		};
	};

	thermal-zones {

		cpu-thermal {
			coefficients = <0xfffffdda 0x6ddd0>;
			phandle = <0xfb>;
			polling-delay = <0x3e8>;
			polling-delay-passive = <0x3e8>;
			thermal-sensors = <0x52>;

			cooling-maps {
				phandle = <0xfd>;

				hot {
					cooling-device = <0x54 0x03 0x03>;
					trip = <0x56>;
				};

				melt {
					cooling-device = <0x54 0x04 0x04>;
					trip = <0x58>;
				};

				tepid {
					cooling-device = <0x54 0x01 0x01>;
					trip = <0x53>;
				};

				vhot {
					cooling-device = <0x54 0x04 0x04>;
					trip = <0x57>;
				};

				warm {
					cooling-device = <0x54 0x02 0x02>;
					trip = <0x55>;
				};
			};

			trips {
				phandle = <0xfc>;

				cpu-crit {
					hysteresis = <0x00>;
					phandle = <0x58>;
					temperature = <0x1adb0>;
					type = "critical";
				};

				cpu-hot {
					hysteresis = <0x1388>;
					phandle = <0x56>;
					temperature = <0x107ac>;
					type = "active";
				};

				cpu-tepid {
					hysteresis = <0x1388>;
					phandle = <0x53>;
					temperature = <0xc350>;
					type = "active";
				};

				cpu-vhot {
					hysteresis = <0x1388>;
					phandle = <0x57>;
					temperature = <0x124f8>;
					type = "active";
				};

				cpu-warm {
					hysteresis = <0x1388>;
					phandle = <0x55>;
					temperature = <0xea60>;
					type = "active";
				};
			};
		};
	};

	timer {
		compatible = "arm,armv8-timer";
		interrupts = <0x01 0x0d 0xf08 0x01 0x0e 0xf08 0x01 0x0b 0xf08 0x01 0x0a 0xf08 0x01 0x0c 0xf08>;
	};

	wl-on-reg {
		compatible = "regulator-fixed";
		enable-active-high;
		gpio = <0x1b 0x1c 0x00>;
		phandle = <0x4b>;
		pinctrl-0 = <0x5a>;
		pinctrl-names = "default";
		regulator-max-microvolt = <0x325aa0>;
		regulator-min-microvolt = <0x325aa0>;
		regulator-name = "wl-on-regulator";
		startup-delay-us = <0x249f0>;
	};
};
